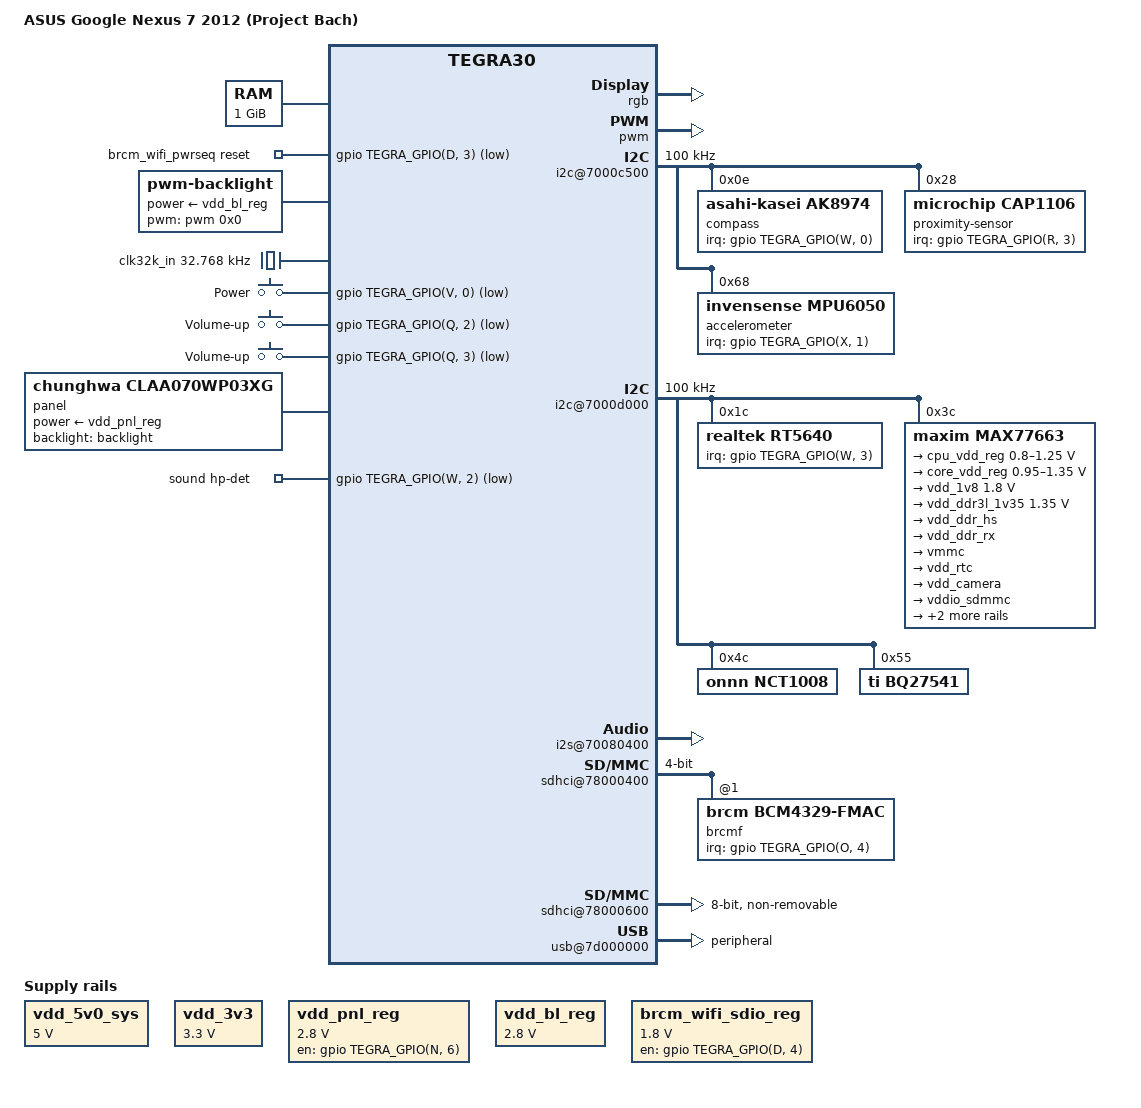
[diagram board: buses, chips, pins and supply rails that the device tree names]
/dts-v1/;

/memreserve/ 0xbeb00000 0x100000;

#include <dt-bindings/input/gpio-keys.h>
#include <dt-bindings/input/input.h>
#include <dt-bindings/mfd/max77620.h>
#include <dt-bindings/thermal/thermal.h>
#include "tegra30.dtsi"
#include "tegra30-cpu-opp.dtsi"
#include "tegra30-cpu-opp-microvolt.dtsi"

/ {
	compatible = "asus,tilapia", "nvidia,tegra30";
	model = "ASUS Google Nexus 7 2012 (Project Bach)";

	aliases {
		rtc0 = "/i2c@7000d000/max77663@3c";
		rtc1 = "/rtc@7000e000";
	};

	memory@80000000 {
		reg = <0x80000000 0x40000000>;
	};

	reserved-memory {
		#address-cells = <1>;
		#size-cells = <1>;
		ranges;

		linux,cma {
			compatible = "shared-dma-pool";
			alloc-ranges = <0x80000000 0x3fe00000>;
			size = <0x10000000>; /* 256MiB */
			linux,cma-default;
			reusable;
		};

		trust_zone@bfe00000 {
			reg = <0xbfe00000 0x200000>;
			no-map;
		};

		ramoops: ramoops@bfdf0000 {
			compatible = "ramoops";
			reg = <0xbfdf0000 0x10000>; /* 64kB */
			console-size = <0x4000>; /* 16kB */
			record-size = <0x4000>; /* 16kB */

			status = "disabled";
		};
	};

	host1x@50000000 {
		dc@54200000 {
			rgb {
				status = "okay";

				nvidia,panel = <&panel>;
			};
		};
	};

	pinmux@70000868 {
		pinctrl-names = "default";
		pinctrl-0 = <&state_default>;

		state_default: pinmux {
			clk_32k_out_pa0 {
				nvidia,pins = "clk_32k_out_pa0";
				nvidia,function = "blink";
				nvidia,pull = <TEGRA_PIN_PULL_NONE>;
				nvidia,tristate = <TEGRA_PIN_DISABLE>;
				nvidia,enable-input = <TEGRA_PIN_DISABLE>;
			};
			uart3_cts_n_pa1 {
				nvidia,pins = "uart3_cts_n_pa1";
				nvidia,function = "uartc";
				nvidia,pull = <TEGRA_PIN_PULL_NONE>;
				nvidia,tristate = <TEGRA_PIN_DISABLE>;
				nvidia,enable-input = <TEGRA_PIN_ENABLE>;
			};
			dap2_fs_pa2 {
				nvidia,pins = "dap2_fs_pa2";
				nvidia,function = "i2s1";
				nvidia,pull = <TEGRA_PIN_PULL_NONE>;
				nvidia,tristate = <TEGRA_PIN_DISABLE>;
				nvidia,enable-input = <TEGRA_PIN_ENABLE>;
			};
			dap2_sclk_pa3 {
				nvidia,pins = "dap2_sclk_pa3";
				nvidia,function = "i2s1";
				nvidia,pull = <TEGRA_PIN_PULL_NONE>;
				nvidia,tristate = <TEGRA_PIN_DISABLE>;
				nvidia,enable-input = <TEGRA_PIN_ENABLE>;
			};
			dap2_din_pa4 {
				nvidia,pins = "dap2_din_pa4";
				nvidia,function = "i2s1";
				nvidia,pull = <TEGRA_PIN_PULL_NONE>;
				nvidia,tristate = <TEGRA_PIN_DISABLE>;
				nvidia,enable-input = <TEGRA_PIN_ENABLE>;
			};
			dap2_dout_pa5 {
				nvidia,pins = "dap2_dout_pa5";
				nvidia,function = "i2s1";
				nvidia,pull = <TEGRA_PIN_PULL_NONE>;
				nvidia,tristate = <TEGRA_PIN_DISABLE>;
				nvidia,enable-input = <TEGRA_PIN_ENABLE>;
			};
			sdmmc3_clk_pa6 {
				nvidia,pins = "sdmmc3_clk_pa6";
				nvidia,function = "sdmmc3";
				nvidia,pull = <TEGRA_PIN_PULL_NONE>;
				nvidia,tristate = <TEGRA_PIN_DISABLE>;
				nvidia,enable-input = <TEGRA_PIN_ENABLE>;
			};
			sdmmc3_cmd_pa7 {
				nvidia,pins = "sdmmc3_cmd_pa7";
				nvidia,function = "sdmmc3";
				nvidia,pull = <TEGRA_PIN_PULL_UP>;
				nvidia,tristate = <TEGRA_PIN_DISABLE>;
				nvidia,enable-input = <TEGRA_PIN_ENABLE>;
			};
			gmi_a17_pb0 {
				nvidia,pins = "gmi_a17_pb0";
				nvidia,function = "uartd";
				nvidia,pull = <TEGRA_PIN_PULL_NONE>;
				nvidia,tristate = <TEGRA_PIN_DISABLE>;
				nvidia,enable-input = <TEGRA_PIN_ENABLE>;
			};
			gmi_a18_pb1 {
				nvidia,pins = "gmi_a18_pb1";
				nvidia,function = "uartd";
				nvidia,pull = <TEGRA_PIN_PULL_NONE>;
				nvidia,tristate = <TEGRA_PIN_DISABLE>;
				nvidia,enable-input = <TEGRA_PIN_ENABLE>;
			};
			lcd_pwr0_pb2 {
				nvidia,pins = "lcd_pwr0_pb2";
				nvidia,function = "displaya";
				nvidia,pull = <TEGRA_PIN_PULL_NONE>;
				nvidia,tristate = <TEGRA_PIN_DISABLE>;
				nvidia,enable-input = <TEGRA_PIN_DISABLE>;
			};
			lcd_pclk_pb3 {
				nvidia,pins = "lcd_pclk_pb3";
				nvidia,function = "displaya";
				nvidia,pull = <TEGRA_PIN_PULL_NONE>;
				nvidia,tristate = <TEGRA_PIN_DISABLE>;
				nvidia,enable-input = <TEGRA_PIN_ENABLE>;
			};
			sdmmc3_dat3_pb4 {
				nvidia,pins = "sdmmc3_dat3_pb4";
				nvidia,function = "sdmmc3";
				nvidia,pull = <TEGRA_PIN_PULL_UP>;
				nvidia,tristate = <TEGRA_PIN_DISABLE>;
				nvidia,enable-input = <TEGRA_PIN_ENABLE>;
			};
			sdmmc3_dat2_pb5 {
				nvidia,pins = "sdmmc3_dat2_pb5";
				nvidia,function = "sdmmc3";
				nvidia,pull = <TEGRA_PIN_PULL_UP>;
				nvidia,tristate = <TEGRA_PIN_DISABLE>;
				nvidia,enable-input = <TEGRA_PIN_ENABLE>;
			};
			sdmmc3_dat1_pb6 {
				nvidia,pins = "sdmmc3_dat1_pb6";
				nvidia,function = "sdmmc3";
				nvidia,pull = <TEGRA_PIN_PULL_UP>;
				nvidia,tristate = <TEGRA_PIN_DISABLE>;
				nvidia,enable-input = <TEGRA_PIN_ENABLE>;
			};
			sdmmc3_dat0_pb7 {
				nvidia,pins = "sdmmc3_dat0_pb7";
				nvidia,function = "sdmmc3";
				nvidia,pull = <TEGRA_PIN_PULL_UP>;
				nvidia,tristate = <TEGRA_PIN_DISABLE>;
				nvidia,enable-input = <TEGRA_PIN_ENABLE>;
			};
			uart3_rts_n_pc0 {
				nvidia,pins = "uart3_rts_n_pc0";
				nvidia,function = "uartc";
				nvidia,pull = <TEGRA_PIN_PULL_NONE>;
				nvidia,tristate = <TEGRA_PIN_DISABLE>;
				nvidia,enable-input = <TEGRA_PIN_DISABLE>;
			};
			lcd_pwr1_pc1 {
				nvidia,pins = "lcd_pwr1_pc1";
				nvidia,function = "displaya";
				nvidia,pull = <TEGRA_PIN_PULL_NONE>;
				nvidia,tristate = <TEGRA_PIN_DISABLE>;
				nvidia,enable-input = <TEGRA_PIN_DISABLE>;
			};
			uart2_txd_pc2 {
				nvidia,pins = "uart2_txd_pc2";
				nvidia,function = "uartb";
				nvidia,pull = <TEGRA_PIN_PULL_NONE>;
				nvidia,tristate = <TEGRA_PIN_DISABLE>;
				nvidia,enable-input = <TEGRA_PIN_DISABLE>;
			};
			uart2_rxd_pc3 {
				nvidia,pins = "uart2_rxd_pc3";
				nvidia,function = "uartb";
				nvidia,pull = <TEGRA_PIN_PULL_NONE>;
				nvidia,tristate = <TEGRA_PIN_DISABLE>;
				nvidia,enable-input = <TEGRA_PIN_ENABLE>;
			};
			gen1_i2c_scl_pc4 {
				nvidia,pins = "gen1_i2c_scl_pc4";
				nvidia,function = "i2c1";
				nvidia,pull = <TEGRA_PIN_PULL_NONE>;
				nvidia,tristate = <TEGRA_PIN_DISABLE>;
				nvidia,enable-input = <TEGRA_PIN_ENABLE>;
				nvidia,open-drain = <TEGRA_PIN_DISABLE>;
			};
			gen1_i2c_sda_pc5 {
				nvidia,pins = "gen1_i2c_sda_pc5";
				nvidia,function = "i2c1";
				nvidia,pull = <TEGRA_PIN_PULL_NONE>;
				nvidia,tristate = <TEGRA_PIN_DISABLE>;
				nvidia,enable-input = <TEGRA_PIN_ENABLE>;
				nvidia,open-drain = <TEGRA_PIN_DISABLE>;
			};
			lcd_pwr2_pc6 {
				nvidia,pins = "lcd_pwr2_pc6";
				nvidia,function = "displaya";
				nvidia,pull = <TEGRA_PIN_PULL_DOWN>;
				nvidia,tristate = <TEGRA_PIN_DISABLE>;
				nvidia,enable-input = <TEGRA_PIN_DISABLE>;
			};
			gmi_wp_n_pc7 {
				nvidia,pins = "gmi_wp_n_pc7";
				nvidia,function = "rsvd1";
				nvidia,pull = <TEGRA_PIN_PULL_NONE>;
				nvidia,tristate = <TEGRA_PIN_ENABLE>;
				nvidia,enable-input = <TEGRA_PIN_ENABLE>;
			};
			sdmmc3_dat5_pd0 {
				nvidia,pins = "sdmmc3_dat5_pd0";
				nvidia,function = "sdmmc3";
				nvidia,pull = <TEGRA_PIN_PULL_NONE>;
				nvidia,tristate = <TEGRA_PIN_DISABLE>;
				nvidia,enable-input = <TEGRA_PIN_DISABLE>;
			};
			sdmmc3_dat4_pd1 {
				nvidia,pins = "sdmmc3_dat4_pd1";
				nvidia,function = "sdmmc3";
				nvidia,pull = <TEGRA_PIN_PULL_UP>;
				nvidia,tristate = <TEGRA_PIN_DISABLE>;
				nvidia,enable-input = <TEGRA_PIN_ENABLE>;
			};
			lcd_dc1_pd2 {
				nvidia,pins = "lcd_dc1_pd2";
				nvidia,function = "displaya";
				nvidia,pull = <TEGRA_PIN_PULL_DOWN>;
				nvidia,tristate = <TEGRA_PIN_DISABLE>;
				nvidia,enable-input = <TEGRA_PIN_DISABLE>;
			};
			sdmmc3_dat6_pd3 {
				nvidia,pins = "sdmmc3_dat6_pd3";
				nvidia,function = "sdmmc3";
				nvidia,pull = <TEGRA_PIN_PULL_UP>;
				nvidia,tristate = <TEGRA_PIN_DISABLE>;
				nvidia,enable-input = <TEGRA_PIN_ENABLE>;
			};
			sdmmc3_dat7_pd4 {
				nvidia,pins = "sdmmc3_dat7_pd4";
				nvidia,function = "sdmmc3";
				nvidia,pull = <TEGRA_PIN_PULL_UP>;
				nvidia,tristate = <TEGRA_PIN_DISABLE>;
				nvidia,enable-input = <TEGRA_PIN_ENABLE>;
			};
			vi_d1_pd5 {
				nvidia,pins = "vi_d1_pd5";
				nvidia,function = "sdmmc2";
				nvidia,pull = <TEGRA_PIN_PULL_DOWN>;
				nvidia,tristate = <TEGRA_PIN_ENABLE>;
				nvidia,enable-input = <TEGRA_PIN_ENABLE>;
			};
			vi_vsync_pd6 {
				nvidia,pins = "vi_vsync_pd6";
				nvidia,function = "ddr";
				nvidia,pull = <TEGRA_PIN_PULL_DOWN>;
				nvidia,tristate = <TEGRA_PIN_ENABLE>;
				nvidia,enable-input = <TEGRA_PIN_ENABLE>;
			};
			vi_hsync_pd7 {
				nvidia,pins = "vi_hsync_pd7";
				nvidia,function = "ddr";
				nvidia,pull = <TEGRA_PIN_PULL_DOWN>;
				nvidia,tristate = <TEGRA_PIN_ENABLE>;
				nvidia,enable-input = <TEGRA_PIN_ENABLE>;
			};
			lcd_d0_pe0 {
				nvidia,pins = "lcd_d0_pe0";
				nvidia,function = "displaya";
				nvidia,pull = <TEGRA_PIN_PULL_NONE>;
				nvidia,tristate = <TEGRA_PIN_DISABLE>;
				nvidia,enable-input = <TEGRA_PIN_ENABLE>;
			};
			lcd_d1_pe1 {
				nvidia,pins = "lcd_d1_pe1";
				nvidia,function = "displaya";
				nvidia,pull = <TEGRA_PIN_PULL_NONE>;
				nvidia,tristate = <TEGRA_PIN_DISABLE>;
				nvidia,enable-input = <TEGRA_PIN_ENABLE>;
			};
			lcd_d2_pe2 {
				nvidia,pins = "lcd_d2_pe2";
				nvidia,function = "displaya";
				nvidia,pull = <TEGRA_PIN_PULL_NONE>;
				nvidia,tristate = <TEGRA_PIN_DISABLE>;
				nvidia,enable-input = <TEGRA_PIN_ENABLE>;
			};
			lcd_d3_pe3 {
				nvidia,pins = "lcd_d3_pe3";
				nvidia,function = "displaya";
				nvidia,pull = <TEGRA_PIN_PULL_NONE>;
				nvidia,tristate = <TEGRA_PIN_DISABLE>;
				nvidia,enable-input = <TEGRA_PIN_ENABLE>;
			};
			lcd_d4_pe4 {
				nvidia,pins = "lcd_d4_pe4";
				nvidia,function = "displaya";
				nvidia,pull = <TEGRA_PIN_PULL_NONE>;
				nvidia,tristate = <TEGRA_PIN_DISABLE>;
				nvidia,enable-input = <TEGRA_PIN_ENABLE>;
			};
			lcd_d5_pe5 {
				nvidia,pins = "lcd_d5_pe5";
				nvidia,function = "displaya";
				nvidia,pull = <TEGRA_PIN_PULL_NONE>;
				nvidia,tristate = <TEGRA_PIN_DISABLE>;
				nvidia,enable-input = <TEGRA_PIN_ENABLE>;
			};
			lcd_d6_pe6 {
				nvidia,pins = "lcd_d6_pe6";
				nvidia,function = "displaya";
				nvidia,pull = <TEGRA_PIN_PULL_NONE>;
				nvidia,tristate = <TEGRA_PIN_DISABLE>;
				nvidia,enable-input = <TEGRA_PIN_ENABLE>;
			};
			lcd_d7_pe7 {
				nvidia,pins = "lcd_d7_pe7";
				nvidia,function = "displaya";
				nvidia,pull = <TEGRA_PIN_PULL_NONE>;
				nvidia,tristate = <TEGRA_PIN_DISABLE>;
				nvidia,enable-input = <TEGRA_PIN_ENABLE>;
			};
			lcd_d8_pf0 {
				nvidia,pins = "lcd_d8_pf0";
				nvidia,function = "displaya";
				nvidia,pull = <TEGRA_PIN_PULL_NONE>;
				nvidia,tristate = <TEGRA_PIN_DISABLE>;
				nvidia,enable-input = <TEGRA_PIN_ENABLE>;
			};
			lcd_d9_pf1 {
				nvidia,pins = "lcd_d9_pf1";
				nvidia,function = "displaya";
				nvidia,pull = <TEGRA_PIN_PULL_NONE>;
				nvidia,tristate = <TEGRA_PIN_DISABLE>;
				nvidia,enable-input = <TEGRA_PIN_ENABLE>;
			};
			lcd_d10_pf2 {
				nvidia,pins = "lcd_d10_pf2";
				nvidia,function = "displaya";
				nvidia,pull = <TEGRA_PIN_PULL_NONE>;
				nvidia,tristate = <TEGRA_PIN_DISABLE>;
				nvidia,enable-input = <TEGRA_PIN_ENABLE>;
			};
			lcd_d11_pf3 {
				nvidia,pins = "lcd_d11_pf3";
				nvidia,function = "displaya";
				nvidia,pull = <TEGRA_PIN_PULL_NONE>;
				nvidia,tristate = <TEGRA_PIN_DISABLE>;
				nvidia,enable-input = <TEGRA_PIN_ENABLE>;
			};
			lcd_d12_pf4 {
				nvidia,pins = "lcd_d12_pf4";
				nvidia,function = "displaya";
				nvidia,pull = <TEGRA_PIN_PULL_NONE>;
				nvidia,tristate = <TEGRA_PIN_DISABLE>;
				nvidia,enable-input = <TEGRA_PIN_ENABLE>;
			};
			lcd_d13_pf5 {
				nvidia,pins = "lcd_d13_pf5";
				nvidia,function = "displaya";
				nvidia,pull = <TEGRA_PIN_PULL_NONE>;
				nvidia,tristate = <TEGRA_PIN_DISABLE>;
				nvidia,enable-input = <TEGRA_PIN_ENABLE>;
			};
			lcd_d14_pf6 {
				nvidia,pins = "lcd_d14_pf6";
				nvidia,function = "displaya";
				nvidia,pull = <TEGRA_PIN_PULL_NONE>;
				nvidia,tristate = <TEGRA_PIN_DISABLE>;
				nvidia,enable-input = <TEGRA_PIN_ENABLE>;
			};
			lcd_d15_pf7 {
				nvidia,pins = "lcd_d15_pf7";
				nvidia,function = "displaya";
				nvidia,pull = <TEGRA_PIN_PULL_NONE>;
				nvidia,tristate = <TEGRA_PIN_DISABLE>;
				nvidia,enable-input = <TEGRA_PIN_ENABLE>;
			};
			gmi_ad0_pg0 {
				nvidia,pins = "gmi_ad0_pg0";
				nvidia,function = "rsvd1";
				nvidia,pull = <TEGRA_PIN_PULL_NONE>;
				nvidia,tristate = <TEGRA_PIN_DISABLE>;
				nvidia,enable-input = <TEGRA_PIN_DISABLE>;
			};
			gmi_ad1_pg1 {
				nvidia,pins = "gmi_ad1_pg1";
				nvidia,function = "rsvd1";
				nvidia,pull = <TEGRA_PIN_PULL_NONE>;
				nvidia,tristate = <TEGRA_PIN_DISABLE>;
				nvidia,enable-input = <TEGRA_PIN_DISABLE>;
			};
			gmi_ad2_pg2 {
				nvidia,pins = "gmi_ad2_pg2";
				nvidia,function = "rsvd1";
				nvidia,pull = <TEGRA_PIN_PULL_DOWN>;
				nvidia,tristate = <TEGRA_PIN_DISABLE>;
				nvidia,enable-input = <TEGRA_PIN_DISABLE>;
			};
			gmi_ad3_pg3 {
				nvidia,pins = "gmi_ad3_pg3";
				nvidia,function = "rsvd1";
				nvidia,pull = <TEGRA_PIN_PULL_DOWN>;
				nvidia,tristate = <TEGRA_PIN_DISABLE>;
				nvidia,enable-input = <TEGRA_PIN_DISABLE>;
			};
			gmi_ad4_pg4 {
				nvidia,pins = "gmi_ad4_pg4";
				nvidia,function = "nand";
				nvidia,pull = <TEGRA_PIN_PULL_NONE>;
				nvidia,tristate = <TEGRA_PIN_DISABLE>;
				nvidia,enable-input = <TEGRA_PIN_ENABLE>;
			};
			gmi_ad5_pg5 {
				nvidia,pins = "gmi_ad5_pg5";
				nvidia,function = "nand";
				nvidia,pull = <TEGRA_PIN_PULL_NONE>;
				nvidia,tristate = <TEGRA_PIN_DISABLE>;
				nvidia,enable-input = <TEGRA_PIN_ENABLE>;
			};
			gmi_ad6_pg6 {
				nvidia,pins = "gmi_ad6_pg6";
				nvidia,function = "rsvd1";
				nvidia,pull = <TEGRA_PIN_PULL_DOWN>;
				nvidia,tristate = <TEGRA_PIN_DISABLE>;
				nvidia,enable-input = <TEGRA_PIN_DISABLE>;
			};
			gmi_ad7_pg7 {
				nvidia,pins = "gmi_ad7_pg7";
				nvidia,function = "rsvd1";
				nvidia,pull = <TEGRA_PIN_PULL_DOWN>;
				nvidia,tristate = <TEGRA_PIN_DISABLE>;
				nvidia,enable-input = <TEGRA_PIN_DISABLE>;
			};
			gmi_ad8_ph0 {
				nvidia,pins = "gmi_ad8_ph0";
				nvidia,function = "pwm0";
				nvidia,pull = <TEGRA_PIN_PULL_NONE>;
				nvidia,tristate = <TEGRA_PIN_DISABLE>;
				nvidia,enable-input = <TEGRA_PIN_DISABLE>;
			};
			gmi_ad9_ph1 {
				nvidia,pins = "gmi_ad9_ph1";
				nvidia,function = "rsvd4";
				nvidia,pull = <TEGRA_PIN_PULL_DOWN>;
				nvidia,tristate = <TEGRA_PIN_DISABLE>;
				nvidia,enable-input = <TEGRA_PIN_DISABLE>;
			};
			gmi_ad10_ph2 {
				nvidia,pins = "gmi_ad10_ph2";
				nvidia,function = "pwm2";
				nvidia,pull = <TEGRA_PIN_PULL_NONE>;
				nvidia,tristate = <TEGRA_PIN_ENABLE>;
				nvidia,enable-input = <TEGRA_PIN_DISABLE>;
			};
			gmi_ad11_ph3 {
				nvidia,pins = "gmi_ad11_ph3";
				nvidia,function = "pwm3";
				nvidia,pull = <TEGRA_PIN_PULL_NONE>;
				nvidia,tristate = <TEGRA_PIN_DISABLE>;
				nvidia,enable-input = <TEGRA_PIN_DISABLE>;
			};
			gmi_ad12_ph4 {
				nvidia,pins = "gmi_ad12_ph4";
				nvidia,function = "rsvd1";
				nvidia,pull = <TEGRA_PIN_PULL_NONE>;
				nvidia,tristate = <TEGRA_PIN_ENABLE>;
				nvidia,enable-input = <TEGRA_PIN_ENABLE>;
			};
			gmi_ad13_ph5 {
				nvidia,pins = "gmi_ad13_ph5";
				nvidia,function = "rsvd1";
				nvidia,pull = <TEGRA_PIN_PULL_NONE>;
				nvidia,tristate = <TEGRA_PIN_ENABLE>;
				nvidia,enable-input = <TEGRA_PIN_DISABLE>;
			};
			gmi_ad14_ph6 {
				nvidia,pins = "gmi_ad14_ph6";
				nvidia,function = "rsvd1";
				nvidia,pull = <TEGRA_PIN_PULL_NONE>;
				nvidia,tristate = <TEGRA_PIN_DISABLE>;
				nvidia,enable-input = <TEGRA_PIN_DISABLE>;
			};
			gmi_ad15_ph7 {
				nvidia,pins = "gmi_ad15_ph7";
				nvidia,function = "rsvd1";
				nvidia,pull = <TEGRA_PIN_PULL_UP>;
				nvidia,tristate = <TEGRA_PIN_DISABLE>;
				nvidia,enable-input = <TEGRA_PIN_DISABLE>;
			};
			gmi_wr_n_pi0 {
				nvidia,pins = "gmi_wr_n_pi0";
				nvidia,function = "rsvd1";
				nvidia,pull = <TEGRA_PIN_PULL_NONE>;
				nvidia,tristate = <TEGRA_PIN_ENABLE>;
				nvidia,enable-input = <TEGRA_PIN_DISABLE>;
			};
			gmi_oe_n_pi1 {
				nvidia,pins = "gmi_oe_n_pi1";
				nvidia,function = "rsvd1";
				nvidia,pull = <TEGRA_PIN_PULL_NONE>;
				nvidia,tristate = <TEGRA_PIN_ENABLE>;
				nvidia,enable-input = <TEGRA_PIN_DISABLE>;
			};
			gmi_dqs_pi2 {
				nvidia,pins = "gmi_dqs_pi2";
				nvidia,function = "rsvd1";
				nvidia,pull = <TEGRA_PIN_PULL_NONE>;
				nvidia,tristate = <TEGRA_PIN_DISABLE>;
				nvidia,enable-input = <TEGRA_PIN_ENABLE>;
			};
			gmi_cs6_n_pi3 {
				nvidia,pins = "gmi_cs6_n_pi3";
				nvidia,function = "gmi";
				nvidia,pull = <TEGRA_PIN_PULL_NONE>;
				nvidia,tristate = <TEGRA_PIN_ENABLE>;
				nvidia,enable-input = <TEGRA_PIN_ENABLE>;
			};
			gmi_rst_n_pi4 {
				nvidia,pins = "gmi_rst_n_pi4";
				nvidia,function = "nand";
				nvidia,pull = <TEGRA_PIN_PULL_UP>;
				nvidia,tristate = <TEGRA_PIN_DISABLE>;
				nvidia,enable-input = <TEGRA_PIN_DISABLE>;
			};
			gmi_iordy_pi5 {
				nvidia,pins = "gmi_iordy_pi5";
				nvidia,function = "rsvd1";
				nvidia,pull = <TEGRA_PIN_PULL_UP>;
				nvidia,tristate = <TEGRA_PIN_DISABLE>;
				nvidia,enable-input = <TEGRA_PIN_ENABLE>;
			};
			gmi_cs7_n_pi6 {
				nvidia,pins = "gmi_cs7_n_pi6";
				nvidia,function = "nand";
				nvidia,pull = <TEGRA_PIN_PULL_NONE>;
				nvidia,tristate = <TEGRA_PIN_ENABLE>;
				nvidia,enable-input = <TEGRA_PIN_DISABLE>;
			};
			gmi_wait_pi7 {
				nvidia,pins = "gmi_wait_pi7";
				nvidia,function = "rsvd1";
				nvidia,pull = <TEGRA_PIN_PULL_NONE>;
				nvidia,tristate = <TEGRA_PIN_ENABLE>;
				nvidia,enable-input = <TEGRA_PIN_ENABLE>;
			};
			gmi_cs0_n_pj0 {
				nvidia,pins = "gmi_cs0_n_pj0";
				nvidia,function = "rsvd1";
				nvidia,pull = <TEGRA_PIN_PULL_NONE>;
				nvidia,tristate = <TEGRA_PIN_ENABLE>;
				nvidia,enable-input = <TEGRA_PIN_ENABLE>;
			};
			lcd_de_pj1 {
				nvidia,pins = "lcd_de_pj1";
				nvidia,function = "displaya";
				nvidia,pull = <TEGRA_PIN_PULL_NONE>;
				nvidia,tristate = <TEGRA_PIN_DISABLE>;
				nvidia,enable-input = <TEGRA_PIN_ENABLE>;
			};
			gmi_cs1_n_pj2 {
				nvidia,pins = "gmi_cs1_n_pj2";
				nvidia,function = "rsvd1";
				nvidia,pull = <TEGRA_PIN_PULL_NONE>;
				nvidia,tristate = <TEGRA_PIN_ENABLE>;
				nvidia,enable-input = <TEGRA_PIN_ENABLE>;
			};
			lcd_hsync_pj3 {
				nvidia,pins = "lcd_hsync_pj3";
				nvidia,function = "displaya";
				nvidia,pull = <TEGRA_PIN_PULL_NONE>;
				nvidia,tristate = <TEGRA_PIN_DISABLE>;
				nvidia,enable-input = <TEGRA_PIN_ENABLE>;
			};
			lcd_vsync_pj4 {
				nvidia,pins = "lcd_vsync_pj4";
				nvidia,function = "displaya";
				nvidia,pull = <TEGRA_PIN_PULL_NONE>;
				nvidia,tristate = <TEGRA_PIN_DISABLE>;
				nvidia,enable-input = <TEGRA_PIN_ENABLE>;
			};
			uart2_cts_n_pj5 {
				nvidia,pins = "uart2_cts_n_pj5";
				nvidia,function = "uartb";
				nvidia,pull = <TEGRA_PIN_PULL_NONE>;
				nvidia,tristate = <TEGRA_PIN_DISABLE>;
				nvidia,enable-input = <TEGRA_PIN_ENABLE>;
			};
			uart2_rts_n_pj6 {
				nvidia,pins = "uart2_rts_n_pj6";
				nvidia,function = "uartb";
				nvidia,pull = <TEGRA_PIN_PULL_NONE>;
				nvidia,tristate = <TEGRA_PIN_DISABLE>;
				nvidia,enable-input = <TEGRA_PIN_DISABLE>;
			};
			gmi_a16_pj7 {
				nvidia,pins = "gmi_a16_pj7";
				nvidia,function = "uartd";
				nvidia,pull = <TEGRA_PIN_PULL_NONE>;
				nvidia,tristate = <TEGRA_PIN_DISABLE>;
				nvidia,enable-input = <TEGRA_PIN_DISABLE>;
			};
			gmi_adv_n_pk0 {
				nvidia,pins = "gmi_adv_n_pk0";
				nvidia,function = "rsvd1";
				nvidia,pull = <TEGRA_PIN_PULL_NONE>;
				nvidia,tristate = <TEGRA_PIN_ENABLE>;
				nvidia,enable-input = <TEGRA_PIN_DISABLE>;
			};
			gmi_clk_pk1 {
				nvidia,pins = "gmi_clk_pk1";
				nvidia,function = "nand";
				nvidia,pull = <TEGRA_PIN_PULL_NONE>;
				nvidia,tristate = <TEGRA_PIN_ENABLE>;
				nvidia,enable-input = <TEGRA_PIN_DISABLE>;
			};
			gmi_cs4_n_pk2 {
				nvidia,pins = "gmi_cs4_n_pk2";
				nvidia,function = "rsvd1";
				nvidia,pull = <TEGRA_PIN_PULL_NONE>;
				nvidia,tristate = <TEGRA_PIN_ENABLE>;
				nvidia,enable-input = <TEGRA_PIN_ENABLE>;
			};
			gmi_cs2_n_pk3 {
				nvidia,pins = "gmi_cs2_n_pk3";
				nvidia,function = "rsvd1";
				nvidia,pull = <TEGRA_PIN_PULL_NONE>;
				nvidia,tristate = <TEGRA_PIN_ENABLE>;
				nvidia,enable-input = <TEGRA_PIN_ENABLE>;
			};
			gmi_cs3_n_pk4 {
				nvidia,pins = "gmi_cs3_n_pk4";
				nvidia,function = "rsvd1";
				nvidia,pull = <TEGRA_PIN_PULL_NONE>;
				nvidia,tristate = <TEGRA_PIN_ENABLE>;
				nvidia,enable-input = <TEGRA_PIN_ENABLE>;
			};
			spdif_out_pk5 {
				nvidia,pins = "spdif_out_pk5";
				nvidia,function = "spdif";
				nvidia,pull = <TEGRA_PIN_PULL_NONE>;
				nvidia,tristate = <TEGRA_PIN_DISABLE>;
				nvidia,enable-input = <TEGRA_PIN_DISABLE>;
			};
			spdif_in_pk6 {
				nvidia,pins = "spdif_in_pk6";
				nvidia,function = "spdif";
				nvidia,pull = <TEGRA_PIN_PULL_NONE>;
				nvidia,tristate = <TEGRA_PIN_DISABLE>;
				nvidia,enable-input = <TEGRA_PIN_ENABLE>;
			};
			gmi_a19_pk7 {
				nvidia,pins = "gmi_a19_pk7";
				nvidia,function = "uartd";
				nvidia,pull = <TEGRA_PIN_PULL_NONE>;
				nvidia,tristate = <TEGRA_PIN_DISABLE>;
				nvidia,enable-input = <TEGRA_PIN_DISABLE>;
			};
			vi_d2_pl0 {
				nvidia,pins = "vi_d2_pl0";
				nvidia,function = "sdmmc2";
				nvidia,pull = <TEGRA_PIN_PULL_DOWN>;
				nvidia,tristate = <TEGRA_PIN_ENABLE>;
				nvidia,enable-input = <TEGRA_PIN_ENABLE>;
			};
			vi_d3_pl1 {
				nvidia,pins = "vi_d3_pl1";
				nvidia,function = "sdmmc2";
				nvidia,pull = <TEGRA_PIN_PULL_DOWN>;
				nvidia,tristate = <TEGRA_PIN_ENABLE>;
				nvidia,enable-input = <TEGRA_PIN_ENABLE>;
			};
			vi_d4_pl2 {
				nvidia,pins = "vi_d4_pl2";
				nvidia,function = "vi";
				nvidia,pull = <TEGRA_PIN_PULL_UP>;
				nvidia,tristate = <TEGRA_PIN_DISABLE>;
				nvidia,enable-input = <TEGRA_PIN_ENABLE>;
			};
			vi_d5_pl3 {
				nvidia,pins = "vi_d5_pl3";
				nvidia,function = "sdmmc2";
				nvidia,pull = <TEGRA_PIN_PULL_DOWN>;
				nvidia,tristate = <TEGRA_PIN_ENABLE>;
				nvidia,enable-input = <TEGRA_PIN_ENABLE>;
			};
			vi_d6_pl4 {
				nvidia,pins = "vi_d6_pl4";
				nvidia,function = "vi";
				nvidia,pull = <TEGRA_PIN_PULL_UP>;
				nvidia,tristate = <TEGRA_PIN_DISABLE>;
				nvidia,enable-input = <TEGRA_PIN_ENABLE>;
			};
			vi_d7_pl5 {
				nvidia,pins = "vi_d7_pl5";
				nvidia,function = "sdmmc2";
				nvidia,pull = <TEGRA_PIN_PULL_DOWN>;
				nvidia,tristate = <TEGRA_PIN_ENABLE>;
				nvidia,enable-input = <TEGRA_PIN_ENABLE>;
			};
			vi_d8_pl6 {
				nvidia,pins = "vi_d8_pl6";
				nvidia,function = "sdmmc2";
				nvidia,pull = <TEGRA_PIN_PULL_DOWN>;
				nvidia,tristate = <TEGRA_PIN_ENABLE>;
				nvidia,enable-input = <TEGRA_PIN_ENABLE>;
			};
			vi_d9_pl7 {
				nvidia,pins = "vi_d9_pl7";
				nvidia,function = "sdmmc2";
				nvidia,pull = <TEGRA_PIN_PULL_DOWN>;
				nvidia,tristate = <TEGRA_PIN_ENABLE>;
				nvidia,enable-input = <TEGRA_PIN_ENABLE>;
			};
			lcd_d16_pm0 {
				nvidia,pins = "lcd_d16_pm0";
				nvidia,function = "displaya";
				nvidia,pull = <TEGRA_PIN_PULL_NONE>;
				nvidia,tristate = <TEGRA_PIN_DISABLE>;
				nvidia,enable-input = <TEGRA_PIN_ENABLE>;
			};
			lcd_d17_pm1 {
				nvidia,pins = "lcd_d17_pm1";
				nvidia,function = "displaya";
				nvidia,pull = <TEGRA_PIN_PULL_NONE>;
				nvidia,tristate = <TEGRA_PIN_DISABLE>;
				nvidia,enable-input = <TEGRA_PIN_ENABLE>;
			};
			lcd_d18_pm2 {
				nvidia,pins = "lcd_d18_pm2";
				nvidia,function = "displaya";
				nvidia,pull = <TEGRA_PIN_PULL_NONE>;
				nvidia,tristate = <TEGRA_PIN_DISABLE>;
				nvidia,enable-input = <TEGRA_PIN_ENABLE>;
			};
			lcd_d19_pm3 {
				nvidia,pins = "lcd_d19_pm3";
				nvidia,function = "displaya";
				nvidia,pull = <TEGRA_PIN_PULL_NONE>;
				nvidia,tristate = <TEGRA_PIN_DISABLE>;
				nvidia,enable-input = <TEGRA_PIN_ENABLE>;
			};
			lcd_d20_pm4 {
				nvidia,pins = "lcd_d20_pm4";
				nvidia,function = "displaya";
				nvidia,pull = <TEGRA_PIN_PULL_NONE>;
				nvidia,tristate = <TEGRA_PIN_DISABLE>;
				nvidia,enable-input = <TEGRA_PIN_ENABLE>;
			};
			lcd_d21_pm5 {
				nvidia,pins = "lcd_d21_pm5";
				nvidia,function = "displaya";
				nvidia,pull = <TEGRA_PIN_PULL_NONE>;
				nvidia,tristate = <TEGRA_PIN_DISABLE>;
				nvidia,enable-input = <TEGRA_PIN_ENABLE>;
			};
			lcd_d22_pm6 {
				nvidia,pins = "lcd_d22_pm6";
				nvidia,function = "displaya";
				nvidia,pull = <TEGRA_PIN_PULL_NONE>;
				nvidia,tristate = <TEGRA_PIN_DISABLE>;
				nvidia,enable-input = <TEGRA_PIN_ENABLE>;
			};
			lcd_d23_pm7 {
				nvidia,pins = "lcd_d23_pm7";
				nvidia,function = "displaya";
				nvidia,pull = <TEGRA_PIN_PULL_NONE>;
				nvidia,tristate = <TEGRA_PIN_DISABLE>;
				nvidia,enable-input = <TEGRA_PIN_ENABLE>;
			};
			dap1_fs_pn0 {
				nvidia,pins = "dap1_fs_pn0";
				nvidia,function = "i2s0";
				nvidia,pull = <TEGRA_PIN_PULL_NONE>;
				nvidia,tristate = <TEGRA_PIN_DISABLE>;
				nvidia,enable-input = <TEGRA_PIN_ENABLE>;
			};
			dap1_din_pn1 {
				nvidia,pins = "dap1_din_pn1";
				nvidia,function = "i2s0";
				nvidia,pull = <TEGRA_PIN_PULL_NONE>;
				nvidia,tristate = <TEGRA_PIN_DISABLE>;
				nvidia,enable-input = <TEGRA_PIN_ENABLE>;
			};
			dap1_dout_pn2 {
				nvidia,pins = "dap1_dout_pn2";
				nvidia,function = "i2s0";
				nvidia,pull = <TEGRA_PIN_PULL_NONE>;
				nvidia,tristate = <TEGRA_PIN_DISABLE>;
				nvidia,enable-input = <TEGRA_PIN_ENABLE>;
			};
			dap1_sclk_pn3 {
				nvidia,pins = "dap1_sclk_pn3";
				nvidia,function = "i2s0";
				nvidia,pull = <TEGRA_PIN_PULL_NONE>;
				nvidia,tristate = <TEGRA_PIN_DISABLE>;
				nvidia,enable-input = <TEGRA_PIN_ENABLE>;
			};
			lcd_cs0_n_pn4 {
				nvidia,pins = "lcd_cs0_n_pn4";
				nvidia,function = "displaya";
				nvidia,pull = <TEGRA_PIN_PULL_NONE>;
				nvidia,tristate = <TEGRA_PIN_DISABLE>;
				nvidia,enable-input = <TEGRA_PIN_ENABLE>;
			};
			lcd_sdout_pn5 {
				nvidia,pins = "lcd_sdout_pn5";
				nvidia,function = "displaya";
				nvidia,pull = <TEGRA_PIN_PULL_NONE>;
				nvidia,tristate = <TEGRA_PIN_DISABLE>;
				nvidia,enable-input = <TEGRA_PIN_ENABLE>;
			};
			lcd_dc0_pn6 {
				nvidia,pins = "lcd_dc0_pn6";
				nvidia,function = "displaya";
				nvidia,pull = <TEGRA_PIN_PULL_NONE>;
				nvidia,tristate = <TEGRA_PIN_DISABLE>;
				nvidia,enable-input = <TEGRA_PIN_ENABLE>;
			};
			hdmi_int_pn7 {
				nvidia,pins = "hdmi_int_pn7";
				nvidia,function = "hdmi";
				nvidia,pull = <TEGRA_PIN_PULL_NONE>;
				nvidia,tristate = <TEGRA_PIN_ENABLE>;
				nvidia,enable-input = <TEGRA_PIN_ENABLE>;
			};
			ulpi_data7_po0 {
				nvidia,pins = "ulpi_data7_po0";
				nvidia,function = "uarta";
				nvidia,pull = <TEGRA_PIN_PULL_UP>;
				nvidia,tristate = <TEGRA_PIN_ENABLE>;
				nvidia,enable-input = <TEGRA_PIN_DISABLE>;
			};
			ulpi_data0_po1 {
				nvidia,pins = "ulpi_data0_po1";
				nvidia,function = "uarta";
				nvidia,pull = <TEGRA_PIN_PULL_DOWN>;
				nvidia,tristate = <TEGRA_PIN_ENABLE>;
				nvidia,enable-input = <TEGRA_PIN_DISABLE>;
			};
			ulpi_data1_po2 {
				nvidia,pins = "ulpi_data1_po2";
				nvidia,function = "uarta";
				nvidia,pull = <TEGRA_PIN_PULL_UP>;
				nvidia,tristate = <TEGRA_PIN_ENABLE>;
				nvidia,enable-input = <TEGRA_PIN_ENABLE>;
			};
			ulpi_data2_po3 {
				nvidia,pins = "ulpi_data2_po3";
				nvidia,function = "uarta";
				nvidia,pull = <TEGRA_PIN_PULL_UP>;
				nvidia,tristate = <TEGRA_PIN_ENABLE>;
				nvidia,enable-input = <TEGRA_PIN_ENABLE>;
			};
			ulpi_data3_po4 {
				nvidia,pins = "ulpi_data3_po4";
				nvidia,function = "ulpi";
				nvidia,pull = <TEGRA_PIN_PULL_NONE>;
				nvidia,tristate = <TEGRA_PIN_DISABLE>;
				nvidia,enable-input = <TEGRA_PIN_ENABLE>;
			};
			ulpi_data4_po5 {
				nvidia,pins = "ulpi_data4_po5";
				nvidia,function = "uarta";
				nvidia,pull = <TEGRA_PIN_PULL_UP>;
				nvidia,tristate = <TEGRA_PIN_ENABLE>;
				nvidia,enable-input = <TEGRA_PIN_ENABLE>;
			};
			ulpi_data5_po6 {
				nvidia,pins = "ulpi_data5_po6";
				nvidia,function = "uarta";
				nvidia,pull = <TEGRA_PIN_PULL_UP>;
				nvidia,tristate = <TEGRA_PIN_ENABLE>;
				nvidia,enable-input = <TEGRA_PIN_ENABLE>;
			};
			ulpi_data6_po7 {
				nvidia,pins = "ulpi_data6_po7";
				nvidia,function = "uarta";
				nvidia,pull = <TEGRA_PIN_PULL_UP>;
				nvidia,tristate = <TEGRA_PIN_ENABLE>;
				nvidia,enable-input = <TEGRA_PIN_ENABLE>;
			};
			dap3_fs_pp0 {
				nvidia,pins = "dap3_fs_pp0";
				nvidia,function = "i2s2";
				nvidia,pull = <TEGRA_PIN_PULL_NONE>;
				nvidia,tristate = <TEGRA_PIN_DISABLE>;
				nvidia,enable-input = <TEGRA_PIN_DISABLE>;
			};
			dap3_din_pp1 {
				nvidia,pins = "dap3_din_pp1";
				nvidia,function = "i2s2";
				nvidia,pull = <TEGRA_PIN_PULL_DOWN>;
				nvidia,tristate = <TEGRA_PIN_DISABLE>;
				nvidia,enable-input = <TEGRA_PIN_DISABLE>;
			};
			dap3_dout_pp2 {
				nvidia,pins = "dap3_dout_pp2";
				nvidia,function = "i2s2";
				nvidia,pull = <TEGRA_PIN_PULL_DOWN>;
				nvidia,tristate = <TEGRA_PIN_DISABLE>;
				nvidia,enable-input = <TEGRA_PIN_ENABLE>;
			};
			dap3_sclk_pp3 {
				nvidia,pins = "dap3_sclk_pp3";
				nvidia,function = "i2s2";
				nvidia,pull = <TEGRA_PIN_PULL_NONE>;
				nvidia,tristate = <TEGRA_PIN_DISABLE>;
				nvidia,enable-input = <TEGRA_PIN_DISABLE>;
			};
			dap4_fs_pp4 {
				nvidia,pins = "dap4_fs_pp4";
				nvidia,function = "i2s3";
				nvidia,pull = <TEGRA_PIN_PULL_NONE>;
				nvidia,tristate = <TEGRA_PIN_DISABLE>;
				nvidia,enable-input = <TEGRA_PIN_ENABLE>;
			};
			dap4_din_pp5 {
				nvidia,pins = "dap4_din_pp5";
				nvidia,function = "i2s3";
				nvidia,pull = <TEGRA_PIN_PULL_NONE>;
				nvidia,tristate = <TEGRA_PIN_DISABLE>;
				nvidia,enable-input = <TEGRA_PIN_ENABLE>;
			};
			dap4_dout_pp6 {
				nvidia,pins = "dap4_dout_pp6";
				nvidia,function = "i2s3";
				nvidia,pull = <TEGRA_PIN_PULL_NONE>;
				nvidia,tristate = <TEGRA_PIN_DISABLE>;
				nvidia,enable-input = <TEGRA_PIN_ENABLE>;
			};
			dap4_sclk_pp7 {
				nvidia,pins = "dap4_sclk_pp7";
				nvidia,function = "i2s3";
				nvidia,pull = <TEGRA_PIN_PULL_NONE>;
				nvidia,tristate = <TEGRA_PIN_DISABLE>;
				nvidia,enable-input = <TEGRA_PIN_ENABLE>;
			};
			kb_col0_pq0 {
				nvidia,pins = "kb_col0_pq0";
				nvidia,function = "kbc";
				nvidia,pull = <TEGRA_PIN_PULL_NONE>;
				nvidia,tristate = <TEGRA_PIN_ENABLE>;
				nvidia,enable-input = <TEGRA_PIN_DISABLE>;
			};
			kb_col1_pq1 {
				nvidia,pins = "kb_col1_pq1";
				nvidia,function = "kbc";
				nvidia,pull = <TEGRA_PIN_PULL_NONE>;
				nvidia,tristate = <TEGRA_PIN_ENABLE>;
				nvidia,enable-input = <TEGRA_PIN_DISABLE>;
			};
			kb_col2_pq2 {
				nvidia,pins = "kb_col2_pq2";
				nvidia,function = "rsvd4";
				nvidia,pull = <TEGRA_PIN_PULL_UP>;
				nvidia,tristate = <TEGRA_PIN_ENABLE>;
				nvidia,enable-input = <TEGRA_PIN_ENABLE>;
			};
			kb_col3_pq3 {
				nvidia,pins = "kb_col3_pq3";
				nvidia,function = "rsvd4";
				nvidia,pull = <TEGRA_PIN_PULL_UP>;
				nvidia,tristate = <TEGRA_PIN_ENABLE>;
				nvidia,enable-input = <TEGRA_PIN_ENABLE>;
			};
			kb_col4_pq4 {
				nvidia,pins = "kb_col4_pq4";
				nvidia,function = "kbc";
				nvidia,pull = <TEGRA_PIN_PULL_NONE>;
				nvidia,tristate = <TEGRA_PIN_ENABLE>;
				nvidia,enable-input = <TEGRA_PIN_ENABLE>;
			};
			kb_col5_pq5 {
				nvidia,pins = "kb_col5_pq5";
				nvidia,function = "kbc";
				nvidia,pull = <TEGRA_PIN_PULL_NONE>;
				nvidia,tristate = <TEGRA_PIN_ENABLE>;
				nvidia,enable-input = <TEGRA_PIN_ENABLE>;
			};
			kb_col6_pq6 {
				nvidia,pins = "kb_col6_pq6";
				nvidia,function = "kbc";
				nvidia,pull = <TEGRA_PIN_PULL_UP>;
				nvidia,tristate = <TEGRA_PIN_DISABLE>;
				nvidia,enable-input = <TEGRA_PIN_ENABLE>;
			};
			kb_col7_pq7 {
				nvidia,pins = "kb_col7_pq7";
				nvidia,function = "kbc";
				nvidia,pull = <TEGRA_PIN_PULL_NONE>;
				nvidia,tristate = <TEGRA_PIN_ENABLE>;
				nvidia,enable-input = <TEGRA_PIN_ENABLE>;
			};
			kb_row0_pr0 {
				nvidia,pins = "kb_row0_pr0";
				nvidia,function = "rsvd4";
				nvidia,pull = <TEGRA_PIN_PULL_UP>;
				nvidia,tristate = <TEGRA_PIN_DISABLE>;
				nvidia,enable-input = <TEGRA_PIN_DISABLE>;
			};
			kb_row1_pr1 {
				nvidia,pins = "kb_row1_pr1";
				nvidia,function = "kbc";
				nvidia,pull = <TEGRA_PIN_PULL_NONE>;
				nvidia,tristate = <TEGRA_PIN_ENABLE>;
				nvidia,enable-input = <TEGRA_PIN_DISABLE>;
			};
			kb_row2_pr2 {
				nvidia,pins = "kb_row2_pr2";
				nvidia,function = "kbc";
				nvidia,pull = <TEGRA_PIN_PULL_NONE>;
				nvidia,tristate = <TEGRA_PIN_ENABLE>;
				nvidia,enable-input = <TEGRA_PIN_ENABLE>;
			};
			kb_row3_pr3 {
				nvidia,pins = "kb_row3_pr3";
				nvidia,function = "kbc";
				nvidia,pull = <TEGRA_PIN_PULL_UP>;
				nvidia,tristate = <TEGRA_PIN_DISABLE>;
				nvidia,enable-input = <TEGRA_PIN_ENABLE>;
			};
			kb_row4_pr4 {
				nvidia,pins = "kb_row4_pr4";
				nvidia,function = "kbc";
				nvidia,pull = <TEGRA_PIN_PULL_NONE>;
				nvidia,tristate = <TEGRA_PIN_ENABLE>;
				nvidia,enable-input = <TEGRA_PIN_ENABLE>;
			};
			kb_row5_pr5 {
				nvidia,pins = "kb_row5_pr5";
				nvidia,function = "kbc";
				nvidia,pull = <TEGRA_PIN_PULL_NONE>;
				nvidia,tristate = <TEGRA_PIN_ENABLE>;
				nvidia,enable-input = <TEGRA_PIN_ENABLE>;
			};
			kb_row6_pr6 {
				nvidia,pins = "kb_row6_pr6";
				nvidia,function = "kbc";
				nvidia,pull = <TEGRA_PIN_PULL_NONE>;
				nvidia,tristate = <TEGRA_PIN_DISABLE>;
				nvidia,enable-input = <TEGRA_PIN_DISABLE>;
			};
			kb_row7_pr7 {
				nvidia,pins = "kb_row7_pr7";
				nvidia,function = "kbc";
				nvidia,pull = <TEGRA_PIN_PULL_DOWN>;
				nvidia,tristate = <TEGRA_PIN_DISABLE>;
				nvidia,enable-input = <TEGRA_PIN_DISABLE>;
			};
			kb_row8_ps0 {
				nvidia,pins = "kb_row8_ps0";
				nvidia,function = "kbc";
				nvidia,pull = <TEGRA_PIN_PULL_NONE>;
				nvidia,tristate = <TEGRA_PIN_DISABLE>;
				nvidia,enable-input = <TEGRA_PIN_DISABLE>;
			};
			kb_row9_ps1 {
				nvidia,pins = "kb_row9_ps1";
				nvidia,function = "kbc";
				nvidia,pull = <TEGRA_PIN_PULL_NONE>;
				nvidia,tristate = <TEGRA_PIN_DISABLE>;
				nvidia,enable-input = <TEGRA_PIN_DISABLE>;
			};
			kb_row10_ps2 {
				nvidia,pins = "kb_row10_ps2";
				nvidia,function = "kbc";
				nvidia,pull = <TEGRA_PIN_PULL_NONE>;
				nvidia,tristate = <TEGRA_PIN_DISABLE>;
				nvidia,enable-input = <TEGRA_PIN_DISABLE>;
			};
			kb_row11_ps3 {
				nvidia,pins = "kb_row11_ps3";
				nvidia,function = "kbc";
				nvidia,pull = <TEGRA_PIN_PULL_NONE>;
				nvidia,tristate = <TEGRA_PIN_DISABLE>;
				nvidia,enable-input = <TEGRA_PIN_ENABLE>;
			};
			kb_row12_ps4 {
				nvidia,pins = "kb_row12_ps4";
				nvidia,function = "kbc";
				nvidia,pull = <TEGRA_PIN_PULL_NONE>;
				nvidia,tristate = <TEGRA_PIN_DISABLE>;
				nvidia,enable-input = <TEGRA_PIN_ENABLE>;
			};
			kb_row13_ps5 {
				nvidia,pins = "kb_row13_ps5";
				nvidia,function = "kbc";
				nvidia,pull = <TEGRA_PIN_PULL_UP>;
				nvidia,tristate = <TEGRA_PIN_DISABLE>;
				nvidia,enable-input = <TEGRA_PIN_ENABLE>;
			};
			kb_row14_ps6 {
				nvidia,pins = "kb_row14_ps6";
				nvidia,function = "kbc";
				nvidia,pull = <TEGRA_PIN_PULL_NONE>;
				nvidia,tristate = <TEGRA_PIN_ENABLE>;
				nvidia,enable-input = <TEGRA_PIN_ENABLE>;
			};
			kb_row15_ps7 {
				nvidia,pins = "kb_row15_ps7";
				nvidia,function = "kbc";
				nvidia,pull = <TEGRA_PIN_PULL_NONE>;
				nvidia,tristate = <TEGRA_PIN_DISABLE>;
				nvidia,enable-input = <TEGRA_PIN_ENABLE>;
			};
			vi_pclk_pt0 {
				nvidia,pins = "vi_pclk_pt0";
				nvidia,function = "sdmmc2";
				nvidia,pull = <TEGRA_PIN_PULL_UP>;
				nvidia,tristate = <TEGRA_PIN_ENABLE>;
				nvidia,enable-input = <TEGRA_PIN_ENABLE>;
			};
			vi_mclk_pt1 {
				nvidia,pins = "vi_mclk_pt1";
				nvidia,function = "vi";
				nvidia,pull = <TEGRA_PIN_PULL_DOWN>;
				nvidia,tristate = <TEGRA_PIN_ENABLE>;
				nvidia,enable-input = <TEGRA_PIN_ENABLE>;
			};
			vi_d10_pt2 {
				nvidia,pins = "vi_d10_pt2";
				nvidia,function = "ddr";
				nvidia,pull = <TEGRA_PIN_PULL_DOWN>;
				nvidia,tristate = <TEGRA_PIN_ENABLE>;
				nvidia,enable-input = <TEGRA_PIN_ENABLE>;
			};
			vi_d11_pt3 {
				nvidia,pins = "vi_d11_pt3";
				nvidia,function = "ddr";
				nvidia,pull = <TEGRA_PIN_PULL_DOWN>;
				nvidia,tristate = <TEGRA_PIN_ENABLE>;
				nvidia,enable-input = <TEGRA_PIN_ENABLE>;
			};
			vi_d0_pt4 {
				nvidia,pins = "vi_d0_pt4";
				nvidia,function = "ddr";
				nvidia,pull = <TEGRA_PIN_PULL_DOWN>;
				nvidia,tristate = <TEGRA_PIN_ENABLE>;
				nvidia,enable-input = <TEGRA_PIN_ENABLE>;
			};
			gen2_i2c_scl_pt5 {
				nvidia,pins = "gen2_i2c_scl_pt5";
				nvidia,function = "i2c2";
				nvidia,pull = <TEGRA_PIN_PULL_NONE>;
				nvidia,tristate = <TEGRA_PIN_DISABLE>;
				nvidia,enable-input = <TEGRA_PIN_ENABLE>;
				nvidia,open-drain = <TEGRA_PIN_DISABLE>;
			};
			gen2_i2c_sda_pt6 {
				nvidia,pins = "gen2_i2c_sda_pt6";
				nvidia,function = "i2c2";
				nvidia,pull = <TEGRA_PIN_PULL_NONE>;
				nvidia,tristate = <TEGRA_PIN_DISABLE>;
				nvidia,enable-input = <TEGRA_PIN_ENABLE>;
				nvidia,open-drain = <TEGRA_PIN_DISABLE>;
			};
			sdmmc4_cmd_pt7 {
				nvidia,pins = "sdmmc4_cmd_pt7";
				nvidia,function = "sdmmc4";
				nvidia,pull = <TEGRA_PIN_PULL_UP>;
				nvidia,tristate = <TEGRA_PIN_DISABLE>;
				nvidia,enable-input = <TEGRA_PIN_ENABLE>;
			};
			pu0 {
				nvidia,pins = "pu0";
				nvidia,function = "rsvd4";
				nvidia,pull = <TEGRA_PIN_PULL_NONE>;
				nvidia,tristate = <TEGRA_PIN_DISABLE>;
				nvidia,enable-input = <TEGRA_PIN_ENABLE>;
			};
			pu1 {
				nvidia,pins = "pu1";
				nvidia,function = "rsvd1";
				nvidia,pull = <TEGRA_PIN_PULL_NONE>;
				nvidia,tristate = <TEGRA_PIN_DISABLE>;
				nvidia,enable-input = <TEGRA_PIN_DISABLE>;
			};
			pu2 {
				nvidia,pins = "pu2";
				nvidia,function = "rsvd1";
				nvidia,pull = <TEGRA_PIN_PULL_NONE>;
				nvidia,tristate = <TEGRA_PIN_DISABLE>;
				nvidia,enable-input = <TEGRA_PIN_ENABLE>;
			};
			pu3 {
				nvidia,pins = "pu3";
				nvidia,function = "rsvd4";
				nvidia,pull = <TEGRA_PIN_PULL_DOWN>;
				nvidia,tristate = <TEGRA_PIN_DISABLE>;
				nvidia,enable-input = <TEGRA_PIN_DISABLE>;
			};
			pu4 {
				nvidia,pins = "pu4";
				nvidia,function = "pwm1";
				nvidia,pull = <TEGRA_PIN_PULL_DOWN>;
				nvidia,tristate = <TEGRA_PIN_DISABLE>;
				nvidia,enable-input = <TEGRA_PIN_DISABLE>;
			};
			pu5 {
				nvidia,pins = "pu5";
				nvidia,function = "pwm2";
				nvidia,pull = <TEGRA_PIN_PULL_DOWN>;
				nvidia,tristate = <TEGRA_PIN_DISABLE>;
				nvidia,enable-input = <TEGRA_PIN_ENABLE>;
			};
			pu6 {
				nvidia,pins = "pu6";
				nvidia,function = "rsvd4";
				nvidia,pull = <TEGRA_PIN_PULL_NONE>;
				nvidia,tristate = <TEGRA_PIN_DISABLE>;
				nvidia,enable-input = <TEGRA_PIN_ENABLE>;
			};
			jtag_rtck_pu7 {
				nvidia,pins = "jtag_rtck_pu7";
				nvidia,function = "rtck";
				nvidia,pull = <TEGRA_PIN_PULL_UP>;
				nvidia,tristate = <TEGRA_PIN_DISABLE>;
				nvidia,enable-input = <TEGRA_PIN_ENABLE>;
			};
			pv0 {
				nvidia,pins = "pv0";
				nvidia,function = "rsvd1";
				nvidia,pull = <TEGRA_PIN_PULL_UP>;
				nvidia,tristate = <TEGRA_PIN_ENABLE>;
				nvidia,enable-input = <TEGRA_PIN_ENABLE>;
			};
			pv1 {
				nvidia,pins = "pv1";
				nvidia,function = "rsvd1";
				nvidia,pull = <TEGRA_PIN_PULL_NONE>;
				nvidia,tristate = <TEGRA_PIN_DISABLE>;
				nvidia,enable-input = <TEGRA_PIN_ENABLE>;
			};
			pv2 {
				nvidia,pins = "pv2";
				nvidia,function = "owr";
				nvidia,pull = <TEGRA_PIN_PULL_NONE>;
				nvidia,tristate = <TEGRA_PIN_ENABLE>;
				nvidia,enable-input = <TEGRA_PIN_DISABLE>;
			};
			pv3 {
				nvidia,pins = "pv3";
				nvidia,function = "clk_12m_out";
				nvidia,pull = <TEGRA_PIN_PULL_NONE>;
				nvidia,tristate = <TEGRA_PIN_ENABLE>;
				nvidia,enable-input = <TEGRA_PIN_ENABLE>;
			};
			ddc_scl_pv4 {
				nvidia,pins = "ddc_scl_pv4";
				nvidia,function = "i2c4";
				nvidia,pull = <TEGRA_PIN_PULL_NONE>;
				nvidia,tristate = <TEGRA_PIN_DISABLE>;
				nvidia,enable-input = <TEGRA_PIN_ENABLE>;
			};
			ddc_sda_pv5 {
				nvidia,pins = "ddc_sda_pv5";
				nvidia,function = "i2c4";
				nvidia,pull = <TEGRA_PIN_PULL_NONE>;
				nvidia,tristate = <TEGRA_PIN_DISABLE>;
				nvidia,enable-input = <TEGRA_PIN_ENABLE>;
			};
			crt_hsync_pv6 {
				nvidia,pins = "crt_hsync_pv6";
				nvidia,function = "crt";
				nvidia,pull = <TEGRA_PIN_PULL_NONE>;
				nvidia,tristate = <TEGRA_PIN_DISABLE>;
				nvidia,enable-input = <TEGRA_PIN_DISABLE>;
			};
			crt_vsync_pv7 {
				nvidia,pins = "crt_vsync_pv7";
				nvidia,function = "crt";
				nvidia,pull = <TEGRA_PIN_PULL_NONE>;
				nvidia,tristate = <TEGRA_PIN_DISABLE>;
				nvidia,enable-input = <TEGRA_PIN_DISABLE>;
			};
			lcd_cs1_n_pw0 {
				nvidia,pins = "lcd_cs1_n_pw0";
				nvidia,function = "displaya";
				nvidia,pull = <TEGRA_PIN_PULL_NONE>;
				nvidia,tristate = <TEGRA_PIN_DISABLE>;
				nvidia,enable-input = <TEGRA_PIN_ENABLE>;
			};
			lcd_m1_pw1 {
				nvidia,pins = "lcd_m1_pw1";
				nvidia,function = "displaya";
				nvidia,pull = <TEGRA_PIN_PULL_NONE>;
				nvidia,tristate = <TEGRA_PIN_DISABLE>;
				nvidia,enable-input = <TEGRA_PIN_DISABLE>;
			};
			spi2_cs1_n_pw2 {
				nvidia,pins = "spi2_cs1_n_pw2";
				nvidia,function = "spi2";
				nvidia,pull = <TEGRA_PIN_PULL_NONE>;
				nvidia,tristate = <TEGRA_PIN_DISABLE>;
				nvidia,enable-input = <TEGRA_PIN_ENABLE>;
			};
			spi2_cs2_n_pw3 {
				nvidia,pins = "spi2_cs2_n_pw3";
				nvidia,function = "spi2";
				nvidia,pull = <TEGRA_PIN_PULL_UP>;
				nvidia,tristate = <TEGRA_PIN_DISABLE>;
				nvidia,enable-input = <TEGRA_PIN_ENABLE>;
			};
			clk1_out_pw4 {
				nvidia,pins = "clk1_out_pw4";
				nvidia,function = "extperiph1";
				nvidia,pull = <TEGRA_PIN_PULL_NONE>;
				nvidia,tristate = <TEGRA_PIN_DISABLE>;
				nvidia,enable-input = <TEGRA_PIN_ENABLE>;
			};
			clk2_out_pw5 {
				nvidia,pins = "clk2_out_pw5";
				nvidia,function = "extperiph2";
				nvidia,pull = <TEGRA_PIN_PULL_NONE>;
				nvidia,tristate = <TEGRA_PIN_DISABLE>;
				nvidia,enable-input = <TEGRA_PIN_ENABLE>;
			};
			uart3_txd_pw6 {
				nvidia,pins = "uart3_txd_pw6";
				nvidia,function = "uartc";
				nvidia,pull = <TEGRA_PIN_PULL_NONE>;
				nvidia,tristate = <TEGRA_PIN_DISABLE>;
				nvidia,enable-input = <TEGRA_PIN_DISABLE>;
			};
			uart3_rxd_pw7 {
				nvidia,pins = "uart3_rxd_pw7";
				nvidia,function = "uartc";
				nvidia,pull = <TEGRA_PIN_PULL_NONE>;
				nvidia,tristate = <TEGRA_PIN_DISABLE>;
				nvidia,enable-input = <TEGRA_PIN_ENABLE>;
			};
			spi2_mosi_px0 {
				nvidia,pins = "spi2_mosi_px0";
				nvidia,function = "spi2";
				nvidia,pull = <TEGRA_PIN_PULL_DOWN>;
				nvidia,tristate = <TEGRA_PIN_DISABLE>;
				nvidia,enable-input = <TEGRA_PIN_DISABLE>;
			};
			spi2_miso_px1 {
				nvidia,pins = "spi2_miso_px1";
				nvidia,function = "spi2";
				nvidia,pull = <TEGRA_PIN_PULL_NONE>;
				nvidia,tristate = <TEGRA_PIN_DISABLE>;
				nvidia,enable-input = <TEGRA_PIN_ENABLE>;
			};
			spi2_sck_px2 {
				nvidia,pins = "spi2_sck_px2";
				nvidia,function = "spi2";
				nvidia,pull = <TEGRA_PIN_PULL_NONE>;
				nvidia,tristate = <TEGRA_PIN_DISABLE>;
				nvidia,enable-input = <TEGRA_PIN_ENABLE>;
			};
			spi2_cs0_n_px3 {
				nvidia,pins = "spi2_cs0_n_px3";
				nvidia,function = "spi6";
				nvidia,pull = <TEGRA_PIN_PULL_UP>;
				nvidia,tristate = <TEGRA_PIN_DISABLE>;
				nvidia,enable-input = <TEGRA_PIN_ENABLE>;
			};
			spi1_mosi_px4 {
				nvidia,pins = "spi1_mosi_px4";
				nvidia,function = "spi1";
				nvidia,pull = <TEGRA_PIN_PULL_NONE>;
				nvidia,tristate = <TEGRA_PIN_DISABLE>;
				nvidia,enable-input = <TEGRA_PIN_ENABLE>;
			};
			spi1_sck_px5 {
				nvidia,pins = "spi1_sck_px5";
				nvidia,function = "spi1";
				nvidia,pull = <TEGRA_PIN_PULL_UP>;
				nvidia,tristate = <TEGRA_PIN_DISABLE>;
				nvidia,enable-input = <TEGRA_PIN_ENABLE>;
			};
			spi1_cs0_n_px6 {
				nvidia,pins = "spi1_cs0_n_px6";
				nvidia,function = "spi1";
				nvidia,pull = <TEGRA_PIN_PULL_NONE>;
				nvidia,tristate = <TEGRA_PIN_DISABLE>;
				nvidia,enable-input = <TEGRA_PIN_ENABLE>;
			};
			spi1_miso_px7 {
				nvidia,pins = "spi1_miso_px7";
				nvidia,function = "spi1";
				nvidia,pull = <TEGRA_PIN_PULL_DOWN>;
				nvidia,tristate = <TEGRA_PIN_DISABLE>;
				nvidia,enable-input = <TEGRA_PIN_DISABLE>;
			};
			ulpi_clk_py0 {
				nvidia,pins = "ulpi_clk_py0";
				nvidia,function = "ulpi";
				nvidia,pull = <TEGRA_PIN_PULL_NONE>;
				nvidia,tristate = <TEGRA_PIN_ENABLE>;
				nvidia,enable-input = <TEGRA_PIN_DISABLE>;
			};
			ulpi_dir_py1 {
				nvidia,pins = "ulpi_dir_py1";
				nvidia,function = "ulpi";
				nvidia,pull = <TEGRA_PIN_PULL_NONE>;
				nvidia,tristate = <TEGRA_PIN_ENABLE>;
				nvidia,enable-input = <TEGRA_PIN_DISABLE>;
			};
			ulpi_nxt_py2 {
				nvidia,pins = "ulpi_nxt_py2";
				nvidia,function = "uartd";
				nvidia,pull = <TEGRA_PIN_PULL_DOWN>;
				nvidia,tristate = <TEGRA_PIN_DISABLE>;
				nvidia,enable-input = <TEGRA_PIN_DISABLE>;
			};
			ulpi_stp_py3 {
				nvidia,pins = "ulpi_stp_py3";
				nvidia,function = "uartd";
				nvidia,pull = <TEGRA_PIN_PULL_DOWN>;
				nvidia,tristate = <TEGRA_PIN_DISABLE>;
				nvidia,enable-input = <TEGRA_PIN_ENABLE>;
			};
			sdmmc1_dat3_py4 {
				nvidia,pins = "sdmmc1_dat3_py4";
				nvidia,function = "sdmmc1";
				nvidia,pull = <TEGRA_PIN_PULL_UP>;
				nvidia,tristate = <TEGRA_PIN_DISABLE>;
				nvidia,enable-input = <TEGRA_PIN_ENABLE>;
			};
			sdmmc1_dat2_py5 {
				nvidia,pins = "sdmmc1_dat2_py5";
				nvidia,function = "sdmmc1";
				nvidia,pull = <TEGRA_PIN_PULL_UP>;
				nvidia,tristate = <TEGRA_PIN_DISABLE>;
				nvidia,enable-input = <TEGRA_PIN_ENABLE>;
			};
			sdmmc1_dat1_py6 {
				nvidia,pins = "sdmmc1_dat1_py6";
				nvidia,function = "sdmmc1";
				nvidia,pull = <TEGRA_PIN_PULL_UP>;
				nvidia,tristate = <TEGRA_PIN_DISABLE>;
				nvidia,enable-input = <TEGRA_PIN_ENABLE>;
			};
			sdmmc1_dat0_py7 {
				nvidia,pins = "sdmmc1_dat0_py7";
				nvidia,function = "sdmmc1";
				nvidia,pull = <TEGRA_PIN_PULL_UP>;
				nvidia,tristate = <TEGRA_PIN_DISABLE>;
				nvidia,enable-input = <TEGRA_PIN_ENABLE>;
			};
			sdmmc1_clk_pz0 {
				nvidia,pins = "sdmmc1_clk_pz0";
				nvidia,function = "sdmmc1";
				nvidia,pull = <TEGRA_PIN_PULL_NONE>;
				nvidia,tristate = <TEGRA_PIN_DISABLE>;
				nvidia,enable-input = <TEGRA_PIN_ENABLE>;
			};
			sdmmc1_cmd_pz1 {
				nvidia,pins = "sdmmc1_cmd_pz1";
				nvidia,function = "sdmmc1";
				nvidia,pull = <TEGRA_PIN_PULL_UP>;
				nvidia,tristate = <TEGRA_PIN_DISABLE>;
				nvidia,enable-input = <TEGRA_PIN_ENABLE>;
			};
			lcd_sdin_pz2 {
				nvidia,pins = "lcd_sdin_pz2";
				nvidia,function = "displaya";
				nvidia,pull = <TEGRA_PIN_PULL_NONE>;
				nvidia,tristate = <TEGRA_PIN_DISABLE>;
				nvidia,enable-input = <TEGRA_PIN_ENABLE>;
			};
			lcd_wr_n_pz3 {
				nvidia,pins = "lcd_wr_n_pz3";
				nvidia,function = "displaya";
				nvidia,pull = <TEGRA_PIN_PULL_UP>;
				nvidia,tristate = <TEGRA_PIN_DISABLE>;
				nvidia,enable-input = <TEGRA_PIN_ENABLE>;
			};
			lcd_sck_pz4 {
				nvidia,pins = "lcd_sck_pz4";
				nvidia,function = "displaya";
				nvidia,pull = <TEGRA_PIN_PULL_NONE>;
				nvidia,tristate = <TEGRA_PIN_DISABLE>;
				nvidia,enable-input = <TEGRA_PIN_ENABLE>;
			};
			sys_clk_req_pz5 {
				nvidia,pins = "sys_clk_req_pz5";
				nvidia,function = "sysclk";
				nvidia,pull = <TEGRA_PIN_PULL_NONE>;
				nvidia,tristate = <TEGRA_PIN_DISABLE>;
				nvidia,enable-input = <TEGRA_PIN_DISABLE>;
			};
			pwr_i2c_scl_pz6 {
				nvidia,pins = "pwr_i2c_scl_pz6";
				nvidia,function = "i2cpwr";
				nvidia,pull = <TEGRA_PIN_PULL_NONE>;
				nvidia,tristate = <TEGRA_PIN_DISABLE>;
				nvidia,enable-input = <TEGRA_PIN_ENABLE>;
				nvidia,open-drain = <TEGRA_PIN_ENABLE>;
			};
			pwr_i2c_sda_pz7 {
				nvidia,pins = "pwr_i2c_sda_pz7";
				nvidia,function = "i2cpwr";
				nvidia,pull = <TEGRA_PIN_PULL_NONE>;
				nvidia,tristate = <TEGRA_PIN_DISABLE>;
				nvidia,enable-input = <TEGRA_PIN_ENABLE>;
				nvidia,open-drain = <TEGRA_PIN_ENABLE>;
			};
			sdmmc4_dat0_paa0 {
				nvidia,pins = "sdmmc4_dat0_paa0";
				nvidia,function = "sdmmc4";
				nvidia,pull = <TEGRA_PIN_PULL_UP>;
				nvidia,tristate = <TEGRA_PIN_DISABLE>;
				nvidia,enable-input = <TEGRA_PIN_ENABLE>;
			};
			sdmmc4_dat1_paa1 {
				nvidia,pins = "sdmmc4_dat1_paa1";
				nvidia,function = "sdmmc4";
				nvidia,pull = <TEGRA_PIN_PULL_UP>;
				nvidia,tristate = <TEGRA_PIN_DISABLE>;
				nvidia,enable-input = <TEGRA_PIN_ENABLE>;
			};
			sdmmc4_dat2_paa2 {
				nvidia,pins = "sdmmc4_dat2_paa2";
				nvidia,function = "sdmmc4";
				nvidia,pull = <TEGRA_PIN_PULL_UP>;
				nvidia,tristate = <TEGRA_PIN_DISABLE>;
				nvidia,enable-input = <TEGRA_PIN_ENABLE>;
			};
			sdmmc4_dat3_paa3 {
				nvidia,pins = "sdmmc4_dat3_paa3";
				nvidia,function = "sdmmc4";
				nvidia,pull = <TEGRA_PIN_PULL_UP>;
				nvidia,tristate = <TEGRA_PIN_DISABLE>;
				nvidia,enable-input = <TEGRA_PIN_ENABLE>;
			};
			sdmmc4_dat4_paa4 {
				nvidia,pins = "sdmmc4_dat4_paa4";
				nvidia,function = "sdmmc4";
				nvidia,pull = <TEGRA_PIN_PULL_UP>;
				nvidia,tristate = <TEGRA_PIN_DISABLE>;
				nvidia,enable-input = <TEGRA_PIN_ENABLE>;
			};
			sdmmc4_dat5_paa5 {
				nvidia,pins = "sdmmc4_dat5_paa5";
				nvidia,function = "sdmmc4";
				nvidia,pull = <TEGRA_PIN_PULL_UP>;
				nvidia,tristate = <TEGRA_PIN_DISABLE>;
				nvidia,enable-input = <TEGRA_PIN_ENABLE>;
			};
			sdmmc4_dat6_paa6 {
				nvidia,pins = "sdmmc4_dat6_paa6";
				nvidia,function = "sdmmc4";
				nvidia,pull = <TEGRA_PIN_PULL_UP>;
				nvidia,tristate = <TEGRA_PIN_DISABLE>;
				nvidia,enable-input = <TEGRA_PIN_ENABLE>;
			};
			sdmmc4_dat7_paa7 {
				nvidia,pins = "sdmmc4_dat7_paa7";
				nvidia,function = "sdmmc4";
				nvidia,pull = <TEGRA_PIN_PULL_UP>;
				nvidia,tristate = <TEGRA_PIN_DISABLE>;
				nvidia,enable-input = <TEGRA_PIN_ENABLE>;
			};
			pbb0 {
				nvidia,pins = "pbb0";
				nvidia,function = "rsvd2";
				nvidia,pull = <TEGRA_PIN_PULL_NONE>;
				nvidia,tristate = <TEGRA_PIN_DISABLE>;
				nvidia,enable-input = <TEGRA_PIN_ENABLE>;
			};
			cam_i2c_scl_pbb1 {
				nvidia,pins = "cam_i2c_scl_pbb1";
				nvidia,function = "i2c3";
				nvidia,pull = <TEGRA_PIN_PULL_NONE>;
				nvidia,tristate = <TEGRA_PIN_DISABLE>;
				nvidia,enable-input = <TEGRA_PIN_ENABLE>;
				nvidia,open-drain = <TEGRA_PIN_DISABLE>;
			};
			cam_i2c_sda_pbb2 {
				nvidia,pins = "cam_i2c_sda_pbb2";
				nvidia,function = "i2c3";
				nvidia,pull = <TEGRA_PIN_PULL_NONE>;
				nvidia,tristate = <TEGRA_PIN_DISABLE>;
				nvidia,enable-input = <TEGRA_PIN_ENABLE>;
				nvidia,open-drain = <TEGRA_PIN_DISABLE>;
			};
			pbb3 {
				nvidia,pins = "pbb3";
				nvidia,function = "vgp3";
				nvidia,pull = <TEGRA_PIN_PULL_NONE>;
				nvidia,tristate = <TEGRA_PIN_DISABLE>;
				nvidia,enable-input = <TEGRA_PIN_ENABLE>;
			};
			pbb4 {
				nvidia,pins = "pbb4";
				nvidia,function = "vgp4";
				nvidia,pull = <TEGRA_PIN_PULL_NONE>;
				nvidia,tristate = <TEGRA_PIN_DISABLE>;
				nvidia,enable-input = <TEGRA_PIN_ENABLE>;
			};
			pbb5 {
				nvidia,pins = "pbb5";
				nvidia,function = "vgp5";
				nvidia,pull = <TEGRA_PIN_PULL_NONE>;
				nvidia,tristate = <TEGRA_PIN_DISABLE>;
				nvidia,enable-input = <TEGRA_PIN_ENABLE>;
			};
			pbb6 {
				nvidia,pins = "pbb6";
				nvidia,function = "vgp6";
				nvidia,pull = <TEGRA_PIN_PULL_NONE>;
				nvidia,tristate = <TEGRA_PIN_DISABLE>;
				nvidia,enable-input = <TEGRA_PIN_ENABLE>;
			};
			pbb7 {
				nvidia,pins = "pbb7";
				nvidia,function = "i2s4";
				nvidia,pull = <TEGRA_PIN_PULL_NONE>;
				nvidia,tristate = <TEGRA_PIN_DISABLE>;
				nvidia,enable-input = <TEGRA_PIN_ENABLE>;
			};
			cam_mclk_pcc0 {
				nvidia,pins = "cam_mclk_pcc0";
				nvidia,function = "vi_alt3";
				nvidia,pull = <TEGRA_PIN_PULL_DOWN>;
				nvidia,tristate = <TEGRA_PIN_DISABLE>;
				nvidia,enable-input = <TEGRA_PIN_ENABLE>;
			};
			pcc1 {
				nvidia,pins = "pcc1";
				nvidia,function = "rsvd2";
				nvidia,pull = <TEGRA_PIN_PULL_NONE>;
				nvidia,tristate = <TEGRA_PIN_DISABLE>;
				nvidia,enable-input = <TEGRA_PIN_ENABLE>;
			};
			pcc2 {
				nvidia,pins = "pcc2";
				nvidia,function = "i2s4";
				nvidia,pull = <TEGRA_PIN_PULL_NONE>;
				nvidia,tristate = <TEGRA_PIN_DISABLE>;
				nvidia,enable-input = <TEGRA_PIN_ENABLE>;
			};
			sdmmc4_rst_n_pcc3 {
				nvidia,pins = "sdmmc4_rst_n_pcc3";
				nvidia,function = "rsvd2";
				nvidia,pull = <TEGRA_PIN_PULL_DOWN>;
				nvidia,tristate = <TEGRA_PIN_DISABLE>;
				nvidia,enable-input = <TEGRA_PIN_ENABLE>;
			};
			sdmmc4_clk_pcc4 {
				nvidia,pins = "sdmmc4_clk_pcc4";
				nvidia,function = "sdmmc4";
				nvidia,pull = <TEGRA_PIN_PULL_NONE>;
				nvidia,tristate = <TEGRA_PIN_DISABLE>;
				nvidia,enable-input = <TEGRA_PIN_ENABLE>;
			};
			clk2_req_pcc5 {
				nvidia,pins = "clk2_req_pcc5";
				nvidia,function = "dap";
				nvidia,pull = <TEGRA_PIN_PULL_NONE>;
				nvidia,tristate = <TEGRA_PIN_DISABLE>;
				nvidia,enable-input = <TEGRA_PIN_ENABLE>;
			};
			pex_l2_rst_n_pcc6 {
				nvidia,pins = "pex_l2_rst_n_pcc6";
				nvidia,function = "pcie";
				nvidia,pull = <TEGRA_PIN_PULL_NONE>;
				nvidia,tristate = <TEGRA_PIN_DISABLE>;
				nvidia,enable-input = <TEGRA_PIN_DISABLE>;
			};
			pex_l2_clkreq_n_pcc7 {
				nvidia,pins = "pex_l2_clkreq_n_pcc7";
				nvidia,function = "pcie";
				nvidia,pull = <TEGRA_PIN_PULL_NONE>;
				nvidia,tristate = <TEGRA_PIN_DISABLE>;
				nvidia,enable-input = <TEGRA_PIN_DISABLE>;
			};
			pex_l0_prsnt_n_pdd0 {
				nvidia,pins = "pex_l0_prsnt_n_pdd0";
				nvidia,function = "pcie";
				nvidia,pull = <TEGRA_PIN_PULL_NONE>;
				nvidia,tristate = <TEGRA_PIN_ENABLE>;
				nvidia,enable-input = <TEGRA_PIN_ENABLE>;
			};
			pex_l0_rst_n_pdd1 {
				nvidia,pins = "pex_l0_rst_n_pdd1";
				nvidia,function = "pcie";
				nvidia,pull = <TEGRA_PIN_PULL_NONE>;
				nvidia,tristate = <TEGRA_PIN_ENABLE>;
				nvidia,enable-input = <TEGRA_PIN_DISABLE>;
			};
			pex_l0_clkreq_n_pdd2 {
				nvidia,pins = "pex_l0_clkreq_n_pdd2";
				nvidia,function = "pcie";
				nvidia,pull = <TEGRA_PIN_PULL_NONE>;
				nvidia,tristate = <TEGRA_PIN_ENABLE>;
				nvidia,enable-input = <TEGRA_PIN_ENABLE>;
			};
			pex_wake_n_pdd3 {
				nvidia,pins = "pex_wake_n_pdd3";
				nvidia,function = "pcie";
				nvidia,pull = <TEGRA_PIN_PULL_NONE>;
				nvidia,tristate = <TEGRA_PIN_DISABLE>;
				nvidia,enable-input = <TEGRA_PIN_ENABLE>;
			};
			pex_l1_prsnt_n_pdd4 {
				nvidia,pins = "pex_l1_prsnt_n_pdd4";
				nvidia,function = "pcie";
				nvidia,pull = <TEGRA_PIN_PULL_NONE>;
				nvidia,tristate = <TEGRA_PIN_ENABLE>;
				nvidia,enable-input = <TEGRA_PIN_ENABLE>;
			};
			pex_l1_rst_n_pdd5 {
				nvidia,pins = "pex_l1_rst_n_pdd5";
				nvidia,function = "pcie";
				nvidia,pull = <TEGRA_PIN_PULL_NONE>;
				nvidia,tristate = <TEGRA_PIN_ENABLE>;
				nvidia,enable-input = <TEGRA_PIN_DISABLE>;
			};
			pex_l1_clkreq_n_pdd6 {
				nvidia,pins = "pex_l1_clkreq_n_pdd6";
				nvidia,function = "pcie";
				nvidia,pull = <TEGRA_PIN_PULL_NONE>;
				nvidia,tristate = <TEGRA_PIN_ENABLE>;
				nvidia,enable-input = <TEGRA_PIN_ENABLE>;
			};
			pex_l2_prsnt_n_pdd7 {
				nvidia,pins = "pex_l2_prsnt_n_pdd7";
				nvidia,function = "pcie";
				nvidia,pull = <TEGRA_PIN_PULL_NONE>;
				nvidia,tristate = <TEGRA_PIN_DISABLE>;
				nvidia,enable-input = <TEGRA_PIN_ENABLE>;
			};
			clk3_out_pee0 {
				nvidia,pins = "clk3_out_pee0";
				nvidia,function = "extperiph3";
				nvidia,pull = <TEGRA_PIN_PULL_NONE>;
				nvidia,tristate = <TEGRA_PIN_DISABLE>;
				nvidia,enable-input = <TEGRA_PIN_DISABLE>;
			};
			clk3_req_pee1 {
				nvidia,pins = "clk3_req_pee1";
				nvidia,function = "dev3";
				nvidia,pull = <TEGRA_PIN_PULL_DOWN>;
				nvidia,tristate = <TEGRA_PIN_DISABLE>;
				nvidia,enable-input = <TEGRA_PIN_ENABLE>;
			};
			clk1_req_pee2 {
				nvidia,pins = "clk1_req_pee2";
				nvidia,function = "dap";
				nvidia,pull = <TEGRA_PIN_PULL_NONE>;
				nvidia,tristate = <TEGRA_PIN_ENABLE>;
				nvidia,enable-input = <TEGRA_PIN_DISABLE>;
			};
			hdmi_cec_pee3 {
				nvidia,pins = "hdmi_cec_pee3";
				nvidia,function = "cec";
				nvidia,pull = <TEGRA_PIN_PULL_NONE>;
				nvidia,tristate = <TEGRA_PIN_DISABLE>;
				nvidia,enable-input = <TEGRA_PIN_ENABLE>;
				nvidia,open-drain = <TEGRA_PIN_DISABLE>;
			};
			owr {
				nvidia,pins = "owr";
				nvidia,function = "owr";
				nvidia,pull = <TEGRA_PIN_PULL_NONE>;
				nvidia,tristate = <TEGRA_PIN_DISABLE>;
				nvidia,enable-input = <TEGRA_PIN_ENABLE>;
			};
			drive_dap1 {
				nvidia,pins = "drive_dap1";
				nvidia,high-speed-mode = <0>;
				nvidia,schmitt = <TEGRA_PIN_ENABLE>;
				nvidia,low-power-mode = <TEGRA_PIN_LP_DRIVE_DIV_1>;
				nvidia,pull-down-strength = <31>;
				nvidia,pull-up-strength = <31>;
				nvidia,slew-rate-rising = <TEGRA_PIN_SLEW_RATE_FASTEST>;
				nvidia,slew-rate-falling = <TEGRA_PIN_SLEW_RATE_FASTEST>;
			};
			drive_dap2 {
				nvidia,pins = "drive_dap2";
				nvidia,high-speed-mode = <0>;
				nvidia,schmitt = <TEGRA_PIN_ENABLE>;
				nvidia,low-power-mode = <TEGRA_PIN_LP_DRIVE_DIV_1>;
				nvidia,pull-down-strength = <31>;
				nvidia,pull-up-strength = <31>;
				nvidia,slew-rate-rising = <TEGRA_PIN_SLEW_RATE_FASTEST>;
				nvidia,slew-rate-falling = <TEGRA_PIN_SLEW_RATE_FASTEST>;
			};
			drive_dbg {
				nvidia,pins = "drive_dbg";
				nvidia,high-speed-mode = <0>;
				nvidia,schmitt = <TEGRA_PIN_ENABLE>;
				nvidia,low-power-mode = <TEGRA_PIN_LP_DRIVE_DIV_1>;
				nvidia,pull-down-strength = <31>;
				nvidia,pull-up-strength = <31>;
				nvidia,slew-rate-rising = <TEGRA_PIN_SLEW_RATE_FASTEST>;
				nvidia,slew-rate-falling = <TEGRA_PIN_SLEW_RATE_FASTEST>;
			};
			drive_at5 {
				nvidia,pins = "drive_at5";
				nvidia,high-speed-mode = <0>;
				nvidia,schmitt = <TEGRA_PIN_ENABLE>;
				nvidia,low-power-mode = <TEGRA_PIN_LP_DRIVE_DIV_1>;
				nvidia,pull-down-strength = <31>;
				nvidia,pull-up-strength = <31>;
				nvidia,slew-rate-rising = <TEGRA_PIN_SLEW_RATE_FASTEST>;
				nvidia,slew-rate-falling = <TEGRA_PIN_SLEW_RATE_FASTEST>;
			};
			drive_gme {
				nvidia,pins = "drive_gme";
				nvidia,high-speed-mode = <0>;
				nvidia,schmitt = <TEGRA_PIN_ENABLE>;
				nvidia,low-power-mode = <TEGRA_PIN_LP_DRIVE_DIV_1>;
				nvidia,pull-down-strength = <31>;
				nvidia,pull-up-strength = <31>;
				nvidia,slew-rate-rising = <TEGRA_PIN_SLEW_RATE_FASTEST>;
				nvidia,slew-rate-falling = <TEGRA_PIN_SLEW_RATE_FASTEST>;
			};
			drive_ddc {
				nvidia,pins = "drive_ddc";
				nvidia,high-speed-mode = <0>;
				nvidia,schmitt = <TEGRA_PIN_ENABLE>;
				nvidia,low-power-mode = <TEGRA_PIN_LP_DRIVE_DIV_1>;
				nvidia,pull-down-strength = <31>;
				nvidia,pull-up-strength = <31>;
				nvidia,slew-rate-rising = <TEGRA_PIN_SLEW_RATE_FASTEST>;
				nvidia,slew-rate-falling = <TEGRA_PIN_SLEW_RATE_FASTEST>;
			};
			drive_ao1 {
				nvidia,pins = "drive_ao1";
				nvidia,high-speed-mode = <0>;
				nvidia,schmitt = <TEGRA_PIN_ENABLE>;
				nvidia,low-power-mode = <TEGRA_PIN_LP_DRIVE_DIV_1>;
				nvidia,pull-down-strength = <31>;
				nvidia,pull-up-strength = <31>;
				nvidia,slew-rate-rising = <TEGRA_PIN_SLEW_RATE_FASTEST>;
				nvidia,slew-rate-falling = <TEGRA_PIN_SLEW_RATE_FASTEST>;
			};
			drive_uart3 {
				nvidia,pins = "drive_uart3";
				nvidia,high-speed-mode = <0>;
				nvidia,schmitt = <TEGRA_PIN_ENABLE>;
				nvidia,low-power-mode = <TEGRA_PIN_LP_DRIVE_DIV_1>;
				nvidia,pull-down-strength = <31>;
				nvidia,pull-up-strength = <31>;
				nvidia,slew-rate-rising = <TEGRA_PIN_SLEW_RATE_FASTEST>;
				nvidia,slew-rate-falling = <TEGRA_PIN_SLEW_RATE_FASTEST>;
			};
			drive_sdio1 {
				nvidia,pins = "drive_sdio1";
				nvidia,high-speed-mode = <0>;
				nvidia,schmitt = <TEGRA_PIN_DISABLE>;
				nvidia,pull-down-strength = <46>;
				nvidia,pull-up-strength = <42>;
				nvidia,slew-rate-rising = <TEGRA_PIN_SLEW_RATE_FAST>;
				nvidia,slew-rate-falling = <TEGRA_PIN_SLEW_RATE_FAST>;
			};
			drive_sdio3 {
				nvidia,pins = "drive_sdio3";
				nvidia,high-speed-mode = <0>;
				nvidia,schmitt = <TEGRA_PIN_DISABLE>;
				nvidia,pull-down-strength = <46>;
				nvidia,pull-up-strength = <42>;
				nvidia,slew-rate-rising = <TEGRA_PIN_SLEW_RATE_FAST>;
				nvidia,slew-rate-falling = <TEGRA_PIN_SLEW_RATE_FAST>;
			};
			drive_gma {
				nvidia,pins = "drive_gma";
				nvidia,pull-down-strength = <9>;
				nvidia,pull-up-strength = <9>;
				nvidia,slew-rate-rising = <TEGRA_PIN_SLEW_RATE_SLOWEST>;
				nvidia,slew-rate-falling = <TEGRA_PIN_SLEW_RATE_SLOWEST>;
			};
			drive_gmb {
				nvidia,pins = "drive_gmb";
				nvidia,pull-down-strength = <9>;
				nvidia,pull-up-strength = <9>;
				nvidia,slew-rate-rising = <TEGRA_PIN_SLEW_RATE_SLOWEST>;
				nvidia,slew-rate-falling = <TEGRA_PIN_SLEW_RATE_SLOWEST>;
			};
			drive_gmc {
				nvidia,pins = "drive_gmc";
				nvidia,pull-down-strength = <9>;
				nvidia,pull-up-strength = <9>;
				nvidia,slew-rate-rising = <TEGRA_PIN_SLEW_RATE_SLOWEST>;
				nvidia,slew-rate-falling = <TEGRA_PIN_SLEW_RATE_SLOWEST>;
			};
			drive_gmd {
				nvidia,pins = "drive_gmd";
				nvidia,pull-down-strength = <9>;
				nvidia,pull-up-strength = <9>;
				nvidia,slew-rate-rising = <TEGRA_PIN_SLEW_RATE_SLOWEST>;
				nvidia,slew-rate-falling = <TEGRA_PIN_SLEW_RATE_SLOWEST>;
			};
		};
	};

	pwm: pwm@7000a000 {
		status = "okay";
	};

	i2c@7000c500 {
		clock-frequency = <100000>;
		status = "okay";

		compass@e {
			compatible = "asahi-kasei,ak8974";
			reg = <0x0e>;
			interrupt-parent = <&gpio>;
			interrupts = <TEGRA_GPIO(W, 0) IRQ_TYPE_EDGE_RISING>;
			mount-matrix =	 "0", "-1",  "0",
					"-1",  "0",  "0",
					 "0",  "0", "-1";
		};

		proximity-sensor@28 {
			compatible = "microchip,cap1106";
			interrupt-parent = <&gpio>;
			interrupts = <TEGRA_GPIO(R, 3) IRQ_TYPE_LEVEL_HIGH>;
			reg = <0x28>;

			microchip,irq-active-high;

			linux,keycodes = <KEY_RESERVED>,
					 <KEY_RESERVED>,
					 <KEY_RESERVED>,
					 <KEY_RESERVED>,
					 <KEY_RESERVED>,
					 <KEY_WAKEUP>;

			#address-cells = <1>;
			#size-cells = <0>;

			proximity@1 {
				label = "cap1106:proximity-sense-cs2";
				reg = <1>;
			};

			proximity@5 {
				label = "cap1106:proximity-sense-cs6";
				reg = <5>;
			};
		};

		accelerometer@68 {
			compatible = "invensense,mpu6050";
			reg = <0x68>;
			interrupt-parent = <&gpio>;
			interrupts = <TEGRA_GPIO(X, 1) IRQ_TYPE_EDGE_RISING>;
			mount-matrix =	 "0", "1",  "0",
					 "1", "0",  "0",
					 "0", "0", "-1";
		};
	};

	i2c@7000d000 {
		clock-frequency = <100000>;
		status = "okay";

		rt5640: rt5640@1c {
			compatible = "realtek,rt5640";
			reg = <0x1c>;
			interrupt-parent = <&gpio>;
			interrupts = <TEGRA_GPIO(W, 3) IRQ_TYPE_EDGE_FALLING>;
			realtek,dmic1-data-pin = <1>;
			realtek,dmic2-data-pin = <0>;
			realtek,in1-differential;
		};

		max77663@3c {
			compatible = "maxim,max77663";
			interrupts = <GIC_SPI 86 IRQ_TYPE_LEVEL_HIGH>;
			reg = <0x3c>;

			system-power-controller;

			fps {
				fps0 {
					maxim,fps-event-source = <MAX77620_FPS_EVENT_SRC_EN0>;
				};

				fps1 {
					maxim,fps-event-source = <MAX77620_FPS_EVENT_SRC_EN1>;
				};

				fps2 {
					maxim,fps-event-source = <MAX77620_FPS_EVENT_SRC_EN0>;
				};
			};

			regulators {
				in-sd0-supply = <&vdd_5v0_sys>;
				in-sd1-supply = <&vdd_5v0_sys>;
				in-sd2-supply = <&vdd_5v0_sys>;
				in-sd3-supply = <&vdd_5v0_sys>;
				in-sd4-supply = <&vdd_5v0_sys>;

				in-ldo0-1-supply = <&vdd_5v0_sys>;
				in-ldo2-supply = <&vdd_5v0_sys>;
				in-ldo3-5-supply = <&vdd_5v0_sys>;
				in-ldo4-6-supply = <&vdd_5v0_sys>;
				in-ldo7-8-supply = <&vdd_1v8>;

				cpu_vdd_reg: sd0 {
					regulator-name = "vdd_cpu";
					regulator-min-microvolt = <800000>;
					regulator-max-microvolt = <1250000>;
					regulator-coupled-with = <&core_vdd_reg>;
					regulator-coupled-max-spread = <300000>;
					regulator-max-step-microvolt = <100000>;
					regulator-always-on;
					regulator-boot-on;

					nvidia,tegra-cpu-regulator;
				};

				core_vdd_reg: sd1 {
					regulator-name = "vdd_core";
					regulator-min-microvolt = <950000>;
					regulator-max-microvolt = <1350000>;
					regulator-coupled-with = <&cpu_vdd_reg>;
					regulator-coupled-max-spread = <300000>;
					regulator-max-step-microvolt = <100000>;
					regulator-always-on;
					regulator-boot-on;

					nvidia,tegra-core-regulator;
				};

				vdd_1v8: sd2 {
					regulator-name = "vdd_gen1v8";
					regulator-min-microvolt = <1800000>;
					regulator-max-microvolt = <1800000>;
					regulator-always-on;
					regulator-boot-on;
				};

				sd3 {
					regulator-name = "vdd_ddr3l_1v35";
					regulator-min-microvolt = <1350000>;
					regulator-max-microvolt = <1350000>;
					regulator-always-on;
					regulator-boot-on;
				};

				ldo0 {
					regulator-name = "vdd_ddr_hs";
					regulator-always-on;
					regulator-boot-on;
				};

				ldo2 {
					regulator-name = "vdd_ddr_rx";
					regulator-always-on;
					regulator-boot-on;
				};

				ldo3 {
					regulator-name = "vmmc";
				};

				ldo4 {
					regulator-name = "vdd_rtc";
					regulator-always-on;
				};

				ldo5 {
					regulator-name = "vdd_camera";
				};

				ldo6 {
					regulator-name = "vddio_sdmmc";
				};

				ldo7 {
					regulator-name = "avdd_dsi_csi";
				};

				ldo8 {
					regulator-name = "avdd_pll";
					regulator-always-on;
					regulator-boot-on;
				};
			};
		};

		nct1008: temperature-sensor@4c {
			compatible = "onnn,nct1008";
			reg = <0x4c>;
			#thermal-sensor-cells = <1>;
		};

		bq27541@55 {
			compatible = "ti,bq27541";
			reg = <0x55>;
		};
	};

	pmc@7000e400 {
		status = "okay";
		nvidia,invert-interrupt;
		nvidia,suspend-mode = <1>;
		nvidia,cpu-pwr-good-time = <2000>;
		nvidia,cpu-pwr-off-time = <200>;
		nvidia,core-pwr-good-time = <3845 3845>;
		nvidia,core-pwr-off-time = <0>;
		nvidia,core-power-req-active-high;
		nvidia,sys-clock-req-active-high;
	};

	ahub@70080000 {
		i2s@70080400 {
			status = "okay";
		};
	};

	brcm_wifi_pwrseq: wifi-pwrseq {
		compatible = "mmc-pwrseq-simple";
		clocks = <&tegra_car TEGRA30_CLK_BLINK>;
		clock-names = "ext_clock";
		reset-gpios = <&gpio TEGRA_GPIO(D, 3) GPIO_ACTIVE_LOW>;
		post-power-on-delay-ms = <300>;
		power-off-delay-us = <300>;
	};

	sdhci@78000400 {
		#address-cells = <1>;
		#size-cells = <0>;

		status = "okay";
		bus-width = <4>;
		enable-sdio-wakeup;

		mmc-pwrseq = <&brcm_wifi_pwrseq>;
		vqmmc-supply = <&brcm_wifi_sdio_reg>;

		brcmf: brcmf@1 {
			reg = <1>;
			compatible = "brcm,bcm4329-fmac";
			interrupt-parent = <&gpio>;
			interrupts = <TEGRA_GPIO(O, 4) IRQ_TYPE_LEVEL_HIGH>;
			interrupt-names = "host-wake";
		};
	};

	sdhci@78000600 {
		status = "okay";
		bus-width = <8>;
		non-removable;
	};

	usb@7d000000 {
		compatible = "nvidia,tegra30-udc";
		status = "okay";
		dr_mode = "peripheral";
	};

	usb-phy@7d000000 {
		status = "okay";
		dr_mode = "peripheral";
	};

	backlight: backlight {
		compatible = "pwm-backlight";
		power-supply = <&vdd_bl_reg>;
		pwms = <&pwm 0x0 500000>;
		brightness-levels = <0 255>;
		num-interpolated-steps = <255>;
		default-brightness-level = <15>;
	};

	clocks {
		compatible = "simple-bus";
		#address-cells = <1>;
		#size-cells = <0>;

		clk32k_in: clock@0 {
			compatible = "fixed-clock";
			reg=<0>;
			#clock-cells = <0>;
			clock-frequency = <32768>;
			clock-output-names = "max77663-gpio4";
		};
	};

	cpus {
		cpu0: cpu@0 {
			cpu-supply = <&cpu_vdd_reg>;
			operating-points-v2 = <&cpu0_opp_table>;
			#cooling-cells = <2>;
		};

		cpu@1 {
			cpu-supply = <&cpu_vdd_reg>;
			operating-points-v2 = <&cpu0_opp_table>;
		};

		cpu@2 {
			cpu-supply = <&cpu_vdd_reg>;
			operating-points-v2 = <&cpu0_opp_table>;
		};

		cpu@3 {
			cpu-supply = <&cpu_vdd_reg>;
			operating-points-v2 = <&cpu0_opp_table>;
		};
	};

	firmware {
		trusted-foundations {
			compatible = "tlm,trusted-foundations";
			tlm,version-major = <0x0>;
			tlm,version-minor = <0x0>;
		};
	};

	gpio-keys {
		compatible = "gpio-keys";

		power {
			label = "Power";
			gpios = <&gpio TEGRA_GPIO(V, 0) GPIO_ACTIVE_LOW>;
			linux,code = <KEY_POWER>;
			debounce-interval = <10>;
			wakeup-event-action = <EV_ACT_ASSERTED>;
			wakeup-source = <1>;
		};

		volume-up {
			label = "Volume-up";
			gpios = <&gpio TEGRA_GPIO(Q, 2) GPIO_ACTIVE_LOW>;
			linux,code = <KEY_VOLUMEUP>;
			debounce-interval = <10>;
		};

		volume-down {
			label = "Volume-up";
			gpios = <&gpio TEGRA_GPIO(Q, 3) GPIO_ACTIVE_LOW>;
			linux,code = <KEY_VOLUMEDOWN>;
			debounce-interval = <10>;
		};
	};

	panel: panel {
		compatible = "chunghwa,claa070wp03xg";
		power-supply = <&vdd_pnl_reg>;
		backlight = <&backlight>;
	};

	regulators {
		compatible = "simple-bus";
		#address-cells = <1>;
		#size-cells = <0>;

		vdd_5v0_sys: regulator@0 {
			compatible = "regulator-fixed";
			reg = <0>;
			regulator-name = "vdd_5v0";
			regulator-min-microvolt = <5000000>;
			regulator-max-microvolt = <5000000>;
			regulator-always-on;
			regulator-boot-on;
		};

		regulator@1 {
			compatible = "regulator-fixed";
			reg = <1>;
			regulator-name = "vdd_3v3";
			regulator-min-microvolt = <3300000>;
			regulator-max-microvolt = <3300000>;
			regulator-always-on;
			regulator-boot-on;
		};

		vdd_pnl_reg: regulator@2 {
			compatible = "regulator-gpio";
			reg = <2>;
			regulator-name = "vdd_pnl";
			regulator-min-microvolt = <2800000>;
			regulator-max-microvolt = <2800000>;

			enable-gpio = <&gpio TEGRA_GPIO(N, 6) GPIO_ACTIVE_HIGH>;
			gpios = <&gpio TEGRA_GPIO(W, 1) GPIO_ACTIVE_HIGH>;
			gpios-states = <1>;
			states = <2800000 1 2800000 0>;

			startup-delay-us = <5000>;
			enable-active-high;
		};

		vdd_bl_reg: regulator@3 {
			compatible = "regulator-fixed";
			reg = <3>;
			regulator-name = "vdd_bl";
			regulator-min-microvolt = <2800000>;
			regulator-max-microvolt = <2800000>;
			regulator-enable-ramp-delay = <300000>;
		};

		brcm_wifi_sdio_reg: regulator@4 {
			compatible = "regulator-fixed";
			reg = <4>;
			regulator-name = "brcm_wifi_pwr";
			regulator-min-microvolt = <1800000>;
			regulator-max-microvolt = <1800000>;
			gpio = <&gpio TEGRA_GPIO(D, 4) GPIO_ACTIVE_HIGH>;
			enable-active-high;
		};
	};

	sound {
		compatible = "nvidia,tegra-audio-rt5640-grouper",
			     "nvidia,tegra-audio-rt5640";
		nvidia,model = "NVIDIA Tegra Grouper";

		nvidia,audio-routing =
			"Headphones", "HPOR",
			"Headphones", "HPOL",
			"Speakers", "SPORP",
			"Speakers", "SPORN",
			"Speakers", "SPOLP",
			"Speakers", "SPOLN",
			"Mic Jack", "MICBIAS1",
			"IN2P", "Mic Jack";

		nvidia,i2s-controller = <&tegra_i2s1>;
		nvidia,audio-codec = <&rt5640>;

		nvidia,hp-det-gpios = <&gpio TEGRA_GPIO(W, 2) GPIO_ACTIVE_LOW>;

		clocks = <&tegra_car TEGRA30_CLK_PLL_A>,
			 <&tegra_car TEGRA30_CLK_PLL_A_OUT0>,
			 <&tegra_car TEGRA30_CLK_EXTERN1>;
		clock-names = "pll_a", "pll_a_out0", "mclk";
	};

	thermal-zones {
		nct1008-local {
			polling-delay-passive = <1000>; /* milliseconds */
			polling-delay = <5000>; /* milliseconds */

			thermal-sensors = <&nct1008 0>;

			trips {
				trip0: cpu-alert0 {
					/* start throttling at 50C */
					temperature = <50000>;
					hysteresis = <3000>;
					type = "passive";
				};

				trip1: cpu-crit {
					/* shut down at 60C */
					temperature = <60000>;
					hysteresis = <2000>;
					type = "critical";
				};
			};

			cooling-maps {
				map0 {
					trip = <&trip0>;
					cooling-device = <&cpu0 THERMAL_NO_LIMIT THERMAL_NO_LIMIT>;
				};
			};
		};

		nct1008-remote {
			polling-delay-passive = <1000>; /* milliseconds */
			polling-delay = <0>; /* milliseconds */

			thermal-sensors = <&nct1008 1>;
		};
	};

	memory-controller@7000f000 {
		emc-timings-1 {
			nvidia,ram-code = <1>;

			timing-25500000 {
				clock-frequency = <25500000>;

				nvidia,emem-configuration = <
					0x00020001 /* MC_EMEM_ARB_CFG */
					0xc0000020 /* MC_EMEM_ARB_OUTSTANDING_REQ */
					0x00000001 /* MC_EMEM_ARB_TIMING_RCD */
					0x00000001 /* MC_EMEM_ARB_TIMING_RP */
					0x00000002 /* MC_EMEM_ARB_TIMING_RC */
					0x00000000 /* MC_EMEM_ARB_TIMING_RAS */
					0x00000001 /* MC_EMEM_ARB_TIMING_FAW */
					0x00000001 /* MC_EMEM_ARB_TIMING_RRD */
					0x00000003 /* MC_EMEM_ARB_TIMING_RAP2PRE */
					0x00000008 /* MC_EMEM_ARB_TIMING_WAP2PRE */
					0x00000002 /* MC_EMEM_ARB_TIMING_R2R */
					0x00000001 /* MC_EMEM_ARB_TIMING_W2W */
					0x00000002 /* MC_EMEM_ARB_TIMING_R2W */
					0x00000006 /* MC_EMEM_ARB_TIMING_W2R */
					0x06020102 /* MC_EMEM_ARB_DA_TURNS */
					0x000a0502 /* MC_EMEM_ARB_DA_COVERS */
					0x74830303 /* MC_EMEM_ARB_MISC0 */
					0x001f0000 /* MC_EMEM_ARB_RING1_THROTTLE */
				>;
			};

			timing-51000000 {
				clock-frequency = <51000000>;

				nvidia,emem-configuration = <
					0x00010001 /* MC_EMEM_ARB_CFG */
					0xc0000020 /* MC_EMEM_ARB_OUTSTANDING_REQ */
					0x00000001 /* MC_EMEM_ARB_TIMING_RCD */
					0x00000001 /* MC_EMEM_ARB_TIMING_RP */
					0x00000002 /* MC_EMEM_ARB_TIMING_RC */
					0x00000000 /* MC_EMEM_ARB_TIMING_RAS */
					0x00000001 /* MC_EMEM_ARB_TIMING_FAW */
					0x00000001 /* MC_EMEM_ARB_TIMING_RRD */
					0x00000003 /* MC_EMEM_ARB_TIMING_RAP2PRE */
					0x00000008 /* MC_EMEM_ARB_TIMING_WAP2PRE */
					0x00000002 /* MC_EMEM_ARB_TIMING_R2R */
					0x00000001 /* MC_EMEM_ARB_TIMING_W2W */
					0x00000002 /* MC_EMEM_ARB_TIMING_R2W */
					0x00000006 /* MC_EMEM_ARB_TIMING_W2R */
					0x06020102 /* MC_EMEM_ARB_DA_TURNS */
					0x000a0502 /* MC_EMEM_ARB_DA_COVERS */
					0x73430303 /* MC_EMEM_ARB_MISC0 */
					0x001f0000 /* MC_EMEM_ARB_RING1_THROTTLE */
				>;
			};

			timing-102000000 {
				clock-frequency = <102000000>;

				nvidia,emem-configuration = <
					0x00000001 /* MC_EMEM_ARB_CFG */
					0xc0000030 /* MC_EMEM_ARB_OUTSTANDING_REQ */
					0x00000001 /* MC_EMEM_ARB_TIMING_RCD */
					0x00000001 /* MC_EMEM_ARB_TIMING_RP */
					0x00000003 /* MC_EMEM_ARB_TIMING_RC */
					0x00000000 /* MC_EMEM_ARB_TIMING_RAS */
					0x00000001 /* MC_EMEM_ARB_TIMING_FAW */
					0x00000001 /* MC_EMEM_ARB_TIMING_RRD */
					0x00000003 /* MC_EMEM_ARB_TIMING_RAP2PRE */
					0x00000008 /* MC_EMEM_ARB_TIMING_WAP2PRE */
					0x00000002 /* MC_EMEM_ARB_TIMING_R2R */
					0x00000001 /* MC_EMEM_ARB_TIMING_W2W */
					0x00000002 /* MC_EMEM_ARB_TIMING_R2W */
					0x00000006 /* MC_EMEM_ARB_TIMING_W2R */
					0x06020102 /* MC_EMEM_ARB_DA_TURNS */
					0x000a0503 /* MC_EMEM_ARB_DA_COVERS */
					0x72830504 /* MC_EMEM_ARB_MISC0 */
					0x001f0000 /* MC_EMEM_ARB_RING1_THROTTLE */
				>;
			};

			timing-204000000 {
				clock-frequency = <204000000>;

				nvidia,emem-configuration = <
					0x00000003 /* MC_EMEM_ARB_CFG */
					0xc0000025 /* MC_EMEM_ARB_OUTSTANDING_REQ */
					0x00000001 /* MC_EMEM_ARB_TIMING_RCD */
					0x00000001 /* MC_EMEM_ARB_TIMING_RP */
					0x00000005 /* MC_EMEM_ARB_TIMING_RC */
					0x00000002 /* MC_EMEM_ARB_TIMING_RAS */
					0x00000003 /* MC_EMEM_ARB_TIMING_FAW */
					0x00000001 /* MC_EMEM_ARB_TIMING_RRD */
					0x00000003 /* MC_EMEM_ARB_TIMING_RAP2PRE */
					0x00000008 /* MC_EMEM_ARB_TIMING_WAP2PRE */
					0x00000002 /* MC_EMEM_ARB_TIMING_R2R */
					0x00000001 /* MC_EMEM_ARB_TIMING_W2W */
					0x00000002 /* MC_EMEM_ARB_TIMING_R2W */
					0x00000006 /* MC_EMEM_ARB_TIMING_W2R */
					0x06020102 /* MC_EMEM_ARB_DA_TURNS */
					0x000a0505 /* MC_EMEM_ARB_DA_COVERS */
					0x72440a06 /* MC_EMEM_ARB_MISC0 */
					0x001f0000 /* MC_EMEM_ARB_RING1_THROTTLE */
				>;
			};

			timing-333500000 {
				clock-frequency = <333500000>;

				nvidia,emem-configuration = <
					0x00000005 /* MC_EMEM_ARB_CFG */
					0xc000003d /* MC_EMEM_ARB_OUTSTANDING_REQ */
					0x00000001 /* MC_EMEM_ARB_TIMING_RCD */
					0x00000002 /* MC_EMEM_ARB_TIMING_RP */
					0x00000008 /* MC_EMEM_ARB_TIMING_RC */
					0x00000004 /* MC_EMEM_ARB_TIMING_RAS */
					0x00000004 /* MC_EMEM_ARB_TIMING_FAW */
					0x00000001 /* MC_EMEM_ARB_TIMING_RRD */
					0x00000002 /* MC_EMEM_ARB_TIMING_RAP2PRE */
					0x00000007 /* MC_EMEM_ARB_TIMING_WAP2PRE */
					0x00000002 /* MC_EMEM_ARB_TIMING_R2R */
					0x00000002 /* MC_EMEM_ARB_TIMING_W2W */
					0x00000003 /* MC_EMEM_ARB_TIMING_R2W */
					0x00000006 /* MC_EMEM_ARB_TIMING_W2R */
					0x06030202 /* MC_EMEM_ARB_DA_TURNS */
					0x000b0608 /* MC_EMEM_ARB_DA_COVERS */
					0x70850f09 /* MC_EMEM_ARB_MISC0 */
					0x001f0000 /* MC_EMEM_ARB_RING1_THROTTLE */
				>;
			};

			timing-667000000 {
				clock-frequency = <667000000>;

				nvidia,emem-configuration = <
					0x0000000a /* MC_EMEM_ARB_CFG */
					0xc0000079 /* MC_EMEM_ARB_OUTSTANDING_REQ */
					0x00000003 /* MC_EMEM_ARB_TIMING_RCD */
					0x00000004 /* MC_EMEM_ARB_TIMING_RP */
					0x00000010 /* MC_EMEM_ARB_TIMING_RC */
					0x0000000b /* MC_EMEM_ARB_TIMING_RAS */
					0x0000000a /* MC_EMEM_ARB_TIMING_FAW */
					0x00000001 /* MC_EMEM_ARB_TIMING_RRD */
					0x00000003 /* MC_EMEM_ARB_TIMING_RAP2PRE */
					0x0000000b /* MC_EMEM_ARB_TIMING_WAP2PRE */
					0x00000002 /* MC_EMEM_ARB_TIMING_R2R */
					0x00000002 /* MC_EMEM_ARB_TIMING_W2W */
					0x00000004 /* MC_EMEM_ARB_TIMING_R2W */
					0x00000008 /* MC_EMEM_ARB_TIMING_W2R */
					0x08040202 /* MC_EMEM_ARB_DA_TURNS */
					0x00130b10 /* MC_EMEM_ARB_DA_COVERS */
					0x70ea1f11 /* MC_EMEM_ARB_MISC0 */
					0x001f0000 /* MC_EMEM_ARB_RING1_THROTTLE */
				>;
			};
		};
	};

	memory-controller@7000f400 {
		emc-timings-1 {
			nvidia,ram-code = <1>;

			timing-25500000 {
				clock-frequency = <25500000>;

				nvidia,emc-auto-cal-interval = <0x001fffff>;
				nvidia,emc-mode-1 = <0x80100003>;
				nvidia,emc-mode-2 = <0x80200008>;
				nvidia,emc-mode-reset = <0x80001221>;
				nvidia,emc-zcal-cnt-long = <0x00000040>;
				nvidia,emc-cfg-dyn-self-ref;
				nvidia,emc-cfg-periodic-qrst;

				nvidia,emc-configuration = <
					0x00000001 /* EMC_RC */
					0x00000004 /* EMC_RFC */
					0x00000000 /* EMC_RAS */
					0x00000000 /* EMC_RP */
					0x00000002 /* EMC_R2W */
					0x0000000a /* EMC_W2R */
					0x00000005 /* EMC_R2P */
					0x0000000b /* EMC_W2P */
					0x00000000 /* EMC_RD_RCD */
					0x00000000 /* EMC_WR_RCD */
					0x00000003 /* EMC_RRD */
					0x00000001 /* EMC_REXT */
					0x00000000 /* EMC_WEXT */
					0x00000005 /* EMC_WDV */
					0x00000005 /* EMC_QUSE */
					0x00000004 /* EMC_QRST */
					0x0000000a /* EMC_QSAFE */
					0x0000000b /* EMC_RDV */
					0x000000c0 /* EMC_REFRESH */
					0x00000000 /* EMC_BURST_REFRESH_NUM */
					0x00000030 /* EMC_PRE_REFRESH_REQ_CNT */
					0x00000002 /* EMC_PDEX2WR */
					0x00000002 /* EMC_PDEX2RD */
					0x00000001 /* EMC_PCHG2PDEN */
					0x00000000 /* EMC_ACT2PDEN */
					0x00000007 /* EMC_AR2PDEN */
					0x0000000f /* EMC_RW2PDEN */
					0x00000005 /* EMC_TXSR */
					0x00000005 /* EMC_TXSRDLL */
					0x00000004 /* EMC_TCKE */
					0x00000001 /* EMC_TFAW */
					0x00000000 /* EMC_TRPAB */
					0x00000004 /* EMC_TCLKSTABLE */
					0x00000005 /* EMC_TCLKSTOP */
					0x000000c7 /* EMC_TREFBW */
					0x00000006 /* EMC_QUSE_EXTRA */
					0x00000004 /* EMC_FBIO_CFG6 */
					0x00000000 /* EMC_ODT_WRITE */
					0x00000000 /* EMC_ODT_READ */
					0x00004288 /* EMC_FBIO_CFG5 */
					0x007800a4 /* EMC_CFG_DIG_DLL */
					0x00008000 /* EMC_CFG_DIG_DLL_PERIOD */
					0x000fc000 /* EMC_DLL_XFORM_DQS0 */
					0x000fc000 /* EMC_DLL_XFORM_DQS1 */
					0x000fc000 /* EMC_DLL_XFORM_DQS2 */
					0x000fc000 /* EMC_DLL_XFORM_DQS3 */
					0x000fc000 /* EMC_DLL_XFORM_DQS4 */
					0x000fc000 /* EMC_DLL_XFORM_DQS5 */
					0x000fc000 /* EMC_DLL_XFORM_DQS6 */
					0x000fc000 /* EMC_DLL_XFORM_DQS7 */
					0x00000000 /* EMC_DLL_XFORM_QUSE0 */
					0x00000000 /* EMC_DLL_XFORM_QUSE1 */
					0x00000000 /* EMC_DLL_XFORM_QUSE2 */
					0x00000000 /* EMC_DLL_XFORM_QUSE3 */
					0x00000000 /* EMC_DLL_XFORM_QUSE4 */
					0x00000000 /* EMC_DLL_XFORM_QUSE5 */
					0x00000000 /* EMC_DLL_XFORM_QUSE6 */
					0x00000000 /* EMC_DLL_XFORM_QUSE7 */
					0x00000000 /* EMC_DLI_TRIM_TXDQS0 */
					0x00000000 /* EMC_DLI_TRIM_TXDQS1 */
					0x00000000 /* EMC_DLI_TRIM_TXDQS2 */
					0x00000000 /* EMC_DLI_TRIM_TXDQS3 */
					0x00000000 /* EMC_DLI_TRIM_TXDQS4 */
					0x00000000 /* EMC_DLI_TRIM_TXDQS5 */
					0x00000000 /* EMC_DLI_TRIM_TXDQS6 */
					0x00000000 /* EMC_DLI_TRIM_TXDQS7 */
					0x000fc000 /* EMC_DLL_XFORM_DQ0 */
					0x000fc000 /* EMC_DLL_XFORM_DQ1 */
					0x000fc000 /* EMC_DLL_XFORM_DQ2 */
					0x000fc000 /* EMC_DLL_XFORM_DQ3 */
					0x000002a0 /* EMC_XM2CMDPADCTRL */
					0x0800211c /* EMC_XM2DQSPADCTRL2 */
					0x00000000 /* EMC_XM2DQPADCTRL2 */
					0x77fff884 /* EMC_XM2CLKPADCTRL */
					0x01f1f108 /* EMC_XM2COMPPADCTRL */
					0x05057404 /* EMC_XM2VTTGENPADCTRL */
					0x54000007 /* EMC_XM2VTTGENPADCTRL2 */
					0x08000168 /* EMC_XM2QUSEPADCTRL */
					0x08000000 /* EMC_XM2DQSPADCTRL3 */
					0x00000802 /* EMC_CTT_TERM_CTRL */
					0x00000000 /* EMC_ZCAL_INTERVAL */
					0x00000040 /* EMC_ZCAL_WAIT_CNT */
					0x000c000c /* EMC_MRS_WAIT_CNT */
					0xa0f10000 /* EMC_AUTO_CAL_CONFIG */
					0x00000000 /* EMC_CTT */
					0x00000000 /* EMC_CTT_DURATION */
					0x80000287 /* EMC_DYN_SELF_REF_CONTROL */
					0xe8000000 /* EMC_FBIO_SPARE */
					0xff00ff00 /* EMC_CFG_RSV */
				>;
			};

			timing-51000000 {
				clock-frequency = <51000000>;

				nvidia,emc-auto-cal-interval = <0x001fffff>;
				nvidia,emc-mode-1 = <0x80100003>;
				nvidia,emc-mode-2 = <0x80200008>;
				nvidia,emc-mode-reset = <0x80001221>;
				nvidia,emc-zcal-cnt-long = <0x00000040>;
				nvidia,emc-cfg-dyn-self-ref;
				nvidia,emc-cfg-periodic-qrst;

				nvidia,emc-configuration = <
					0x00000002 /* EMC_RC */
					0x00000008 /* EMC_RFC */
					0x00000001 /* EMC_RAS */
					0x00000000 /* EMC_RP */
					0x00000002 /* EMC_R2W */
					0x0000000a /* EMC_W2R */
					0x00000005 /* EMC_R2P */
					0x0000000b /* EMC_W2P */
					0x00000000 /* EMC_RD_RCD */
					0x00000000 /* EMC_WR_RCD */
					0x00000003 /* EMC_RRD */
					0x00000001 /* EMC_REXT */
					0x00000000 /* EMC_WEXT */
					0x00000005 /* EMC_WDV */
					0x00000005 /* EMC_QUSE */
					0x00000004 /* EMC_QRST */
					0x0000000a /* EMC_QSAFE */
					0x0000000b /* EMC_RDV */
					0x00000181 /* EMC_REFRESH */
					0x00000000 /* EMC_BURST_REFRESH_NUM */
					0x00000060 /* EMC_PRE_REFRESH_REQ_CNT */
					0x00000002 /* EMC_PDEX2WR */
					0x00000002 /* EMC_PDEX2RD */
					0x00000001 /* EMC_PCHG2PDEN */
					0x00000000 /* EMC_ACT2PDEN */
					0x00000007 /* EMC_AR2PDEN */
					0x0000000f /* EMC_RW2PDEN */
					0x00000009 /* EMC_TXSR */
					0x00000009 /* EMC_TXSRDLL */
					0x00000004 /* EMC_TCKE */
					0x00000002 /* EMC_TFAW */
					0x00000000 /* EMC_TRPAB */
					0x00000004 /* EMC_TCLKSTABLE */
					0x00000005 /* EMC_TCLKSTOP */
					0x0000018e /* EMC_TREFBW */
					0x00000006 /* EMC_QUSE_EXTRA */
					0x00000004 /* EMC_FBIO_CFG6 */
					0x00000000 /* EMC_ODT_WRITE */
					0x00000000 /* EMC_ODT_READ */
					0x00004288 /* EMC_FBIO_CFG5 */
					0x007800a4 /* EMC_CFG_DIG_DLL */
					0x00008000 /* EMC_CFG_DIG_DLL_PERIOD */
					0x000fc000 /* EMC_DLL_XFORM_DQS0 */
					0x000fc000 /* EMC_DLL_XFORM_DQS1 */
					0x000fc000 /* EMC_DLL_XFORM_DQS2 */
					0x000fc000 /* EMC_DLL_XFORM_DQS3 */
					0x000fc000 /* EMC_DLL_XFORM_DQS4 */
					0x000fc000 /* EMC_DLL_XFORM_DQS5 */
					0x000fc000 /* EMC_DLL_XFORM_DQS6 */
					0x000fc000 /* EMC_DLL_XFORM_DQS7 */
					0x00000000 /* EMC_DLL_XFORM_QUSE0 */
					0x00000000 /* EMC_DLL_XFORM_QUSE1 */
					0x00000000 /* EMC_DLL_XFORM_QUSE2 */
					0x00000000 /* EMC_DLL_XFORM_QUSE3 */
					0x00000000 /* EMC_DLL_XFORM_QUSE4 */
					0x00000000 /* EMC_DLL_XFORM_QUSE5 */
					0x00000000 /* EMC_DLL_XFORM_QUSE6 */
					0x00000000 /* EMC_DLL_XFORM_QUSE7 */
					0x00000000 /* EMC_DLI_TRIM_TXDQS0 */
					0x00000000 /* EMC_DLI_TRIM_TXDQS1 */
					0x00000000 /* EMC_DLI_TRIM_TXDQS2 */
					0x00000000 /* EMC_DLI_TRIM_TXDQS3 */
					0x00000000 /* EMC_DLI_TRIM_TXDQS4 */
					0x00000000 /* EMC_DLI_TRIM_TXDQS5 */
					0x00000000 /* EMC_DLI_TRIM_TXDQS6 */
					0x00000000 /* EMC_DLI_TRIM_TXDQS7 */
					0x000fc000 /* EMC_DLL_XFORM_DQ0 */
					0x000fc000 /* EMC_DLL_XFORM_DQ1 */
					0x000fc000 /* EMC_DLL_XFORM_DQ2 */
					0x000fc000 /* EMC_DLL_XFORM_DQ3 */
					0x000002a0 /* EMC_XM2CMDPADCTRL */
					0x0800211c /* EMC_XM2DQSPADCTRL2 */
					0x00000000 /* EMC_XM2DQPADCTRL2 */
					0x77fff884 /* EMC_XM2CLKPADCTRL */
					0x01f1f108 /* EMC_XM2COMPPADCTRL */
					0x05057404 /* EMC_XM2VTTGENPADCTRL */
					0x54000007 /* EMC_XM2VTTGENPADCTRL2 */
					0x08000168 /* EMC_XM2QUSEPADCTRL */
					0x08000000 /* EMC_XM2DQSPADCTRL3 */
					0x00000802 /* EMC_CTT_TERM_CTRL */
					0x00000000 /* EMC_ZCAL_INTERVAL */
					0x00000040 /* EMC_ZCAL_WAIT_CNT */
					0x000c000c /* EMC_MRS_WAIT_CNT */
					0xa0f10000 /* EMC_AUTO_CAL_CONFIG */
					0x00000000 /* EMC_CTT */
					0x00000000 /* EMC_CTT_DURATION */
					0x8000040b /* EMC_DYN_SELF_REF_CONTROL */
					0xe8000000 /* EMC_FBIO_SPARE */
					0xff00ff00 /* EMC_CFG_RSV */
				>;
			};

			timing-102000000 {
				clock-frequency = <102000000>;

				nvidia,emc-auto-cal-interval = <0x001fffff>;
				nvidia,emc-mode-1 = <0x80100003>;
				nvidia,emc-mode-2 = <0x80200008>;
				nvidia,emc-mode-reset = <0x80001221>;
				nvidia,emc-zcal-cnt-long = <0x00000040>;
				nvidia,emc-cfg-dyn-self-ref;
				nvidia,emc-cfg-periodic-qrst;

				nvidia,emc-configuration = <
					0x00000005 /* EMC_RC */
					0x00000010 /* EMC_RFC */
					0x00000003 /* EMC_RAS */
					0x00000001 /* EMC_RP */
					0x00000002 /* EMC_R2W */
					0x0000000a /* EMC_W2R */
					0x00000005 /* EMC_R2P */
					0x0000000b /* EMC_W2P */
					0x00000001 /* EMC_RD_RCD */
					0x00000001 /* EMC_WR_RCD */
					0x00000003 /* EMC_RRD */
					0x00000001 /* EMC_REXT */
					0x00000000 /* EMC_WEXT */
					0x00000005 /* EMC_WDV */
					0x00000005 /* EMC_QUSE */
					0x00000004 /* EMC_QRST */
					0x0000000a /* EMC_QSAFE */
					0x0000000b /* EMC_RDV */
					0x00000303 /* EMC_REFRESH */
					0x00000000 /* EMC_BURST_REFRESH_NUM */
					0x000000c0 /* EMC_PRE_REFRESH_REQ_CNT */
					0x00000002 /* EMC_PDEX2WR */
					0x00000002 /* EMC_PDEX2RD */
					0x00000001 /* EMC_PCHG2PDEN */
					0x00000000 /* EMC_ACT2PDEN */
					0x00000007 /* EMC_AR2PDEN */
					0x0000000f /* EMC_RW2PDEN */
					0x00000012 /* EMC_TXSR */
					0x00000012 /* EMC_TXSRDLL */
					0x00000004 /* EMC_TCKE */
					0x00000004 /* EMC_TFAW */
					0x00000000 /* EMC_TRPAB */
					0x00000004 /* EMC_TCLKSTABLE */
					0x00000005 /* EMC_TCLKSTOP */
					0x0000031c /* EMC_TREFBW */
					0x00000006 /* EMC_QUSE_EXTRA */
					0x00000004 /* EMC_FBIO_CFG6 */
					0x00000000 /* EMC_ODT_WRITE */
					0x00000000 /* EMC_ODT_READ */
					0x00004288 /* EMC_FBIO_CFG5 */
					0x007800a4 /* EMC_CFG_DIG_DLL */
					0x00008000 /* EMC_CFG_DIG_DLL_PERIOD */
					0x000fc000 /* EMC_DLL_XFORM_DQS0 */
					0x000fc000 /* EMC_DLL_XFORM_DQS1 */
					0x000fc000 /* EMC_DLL_XFORM_DQS2 */
					0x000fc000 /* EMC_DLL_XFORM_DQS3 */
					0x000fc000 /* EMC_DLL_XFORM_DQS4 */
					0x000fc000 /* EMC_DLL_XFORM_DQS5 */
					0x000fc000 /* EMC_DLL_XFORM_DQS6 */
					0x000fc000 /* EMC_DLL_XFORM_DQS7 */
					0x00000000 /* EMC_DLL_XFORM_QUSE0 */
					0x00000000 /* EMC_DLL_XFORM_QUSE1 */
					0x00000000 /* EMC_DLL_XFORM_QUSE2 */
					0x00000000 /* EMC_DLL_XFORM_QUSE3 */
					0x00000000 /* EMC_DLL_XFORM_QUSE4 */
					0x00000000 /* EMC_DLL_XFORM_QUSE5 */
					0x00000000 /* EMC_DLL_XFORM_QUSE6 */
					0x00000000 /* EMC_DLL_XFORM_QUSE7 */
					0x00000000 /* EMC_DLI_TRIM_TXDQS0 */
					0x00000000 /* EMC_DLI_TRIM_TXDQS1 */
					0x00000000 /* EMC_DLI_TRIM_TXDQS2 */
					0x00000000 /* EMC_DLI_TRIM_TXDQS3 */
					0x00000000 /* EMC_DLI_TRIM_TXDQS4 */
					0x00000000 /* EMC_DLI_TRIM_TXDQS5 */
					0x00000000 /* EMC_DLI_TRIM_TXDQS6 */
					0x00000000 /* EMC_DLI_TRIM_TXDQS7 */
					0x000fc000 /* EMC_DLL_XFORM_DQ0 */
					0x000fc000 /* EMC_DLL_XFORM_DQ1 */
					0x000fc000 /* EMC_DLL_XFORM_DQ2 */
					0x000fc000 /* EMC_DLL_XFORM_DQ3 */
					0x000002a0 /* EMC_XM2CMDPADCTRL */
					0x0800211c /* EMC_XM2DQSPADCTRL2 */
					0x00000000 /* EMC_XM2DQPADCTRL2 */
					0x77fff884 /* EMC_XM2CLKPADCTRL */
					0x01f1f108 /* EMC_XM2COMPPADCTRL */
					0x05057404 /* EMC_XM2VTTGENPADCTRL */
					0x54000007 /* EMC_XM2VTTGENPADCTRL2 */
					0x08000168 /* EMC_XM2QUSEPADCTRL */
					0x08000000 /* EMC_XM2DQSPADCTRL3 */
					0x00000802 /* EMC_CTT_TERM_CTRL */
					0x00000000 /* EMC_ZCAL_INTERVAL */
					0x00000040 /* EMC_ZCAL_WAIT_CNT */
					0x000c000c /* EMC_MRS_WAIT_CNT */
					0xa0f10000 /* EMC_AUTO_CAL_CONFIG */
					0x00000000 /* EMC_CTT */
					0x00000000 /* EMC_CTT_DURATION */
					0x80000713 /* EMC_DYN_SELF_REF_CONTROL */
					0xe8000000 /* EMC_FBIO_SPARE */
					0xff00ff00 /* EMC_CFG_RSV */
				>;
			};

			timing-204000000 {
				clock-frequency = <204000000>;

				nvidia,emc-auto-cal-interval = <0x001fffff>;
				nvidia,emc-mode-1 = <0x80100003>;
				nvidia,emc-mode-2 = <0x80200008>;
				nvidia,emc-mode-reset = <0x80001221>;
				nvidia,emc-zcal-cnt-long = <0x00000040>;
				nvidia,emc-cfg-dyn-self-ref;
				nvidia,emc-cfg-periodic-qrst;

				nvidia,emc-configuration = <
					0x0000000a /* EMC_RC */
					0x00000020 /* EMC_RFC */
					0x00000007 /* EMC_RAS */
					0x00000002 /* EMC_RP */
					0x00000002 /* EMC_R2W */
					0x0000000a /* EMC_W2R */
					0x00000005 /* EMC_R2P */
					0x0000000b /* EMC_W2P */
					0x00000002 /* EMC_RD_RCD */
					0x00000002 /* EMC_WR_RCD */
					0x00000003 /* EMC_RRD */
					0x00000001 /* EMC_REXT */
					0x00000000 /* EMC_WEXT */
					0x00000005 /* EMC_WDV */
					0x00000005 /* EMC_QUSE */
					0x00000004 /* EMC_QRST */
					0x0000000a /* EMC_QSAFE */
					0x0000000b /* EMC_RDV */
					0x00000607 /* EMC_REFRESH */
					0x00000000 /* EMC_BURST_REFRESH_NUM */
					0x00000181 /* EMC_PRE_REFRESH_REQ_CNT */
					0x00000002 /* EMC_PDEX2WR */
					0x00000002 /* EMC_PDEX2RD */
					0x00000001 /* EMC_PCHG2PDEN */
					0x00000000 /* EMC_ACT2PDEN */
					0x00000007 /* EMC_AR2PDEN */
					0x0000000f /* EMC_RW2PDEN */
					0x00000023 /* EMC_TXSR */
					0x00000023 /* EMC_TXSRDLL */
					0x00000004 /* EMC_TCKE */
					0x00000007 /* EMC_TFAW */
					0x00000000 /* EMC_TRPAB */
					0x00000004 /* EMC_TCLKSTABLE */
					0x00000005 /* EMC_TCLKSTOP */
					0x00000638 /* EMC_TREFBW */
					0x00000006 /* EMC_QUSE_EXTRA */
					0x00000006 /* EMC_FBIO_CFG6 */
					0x00000000 /* EMC_ODT_WRITE */
					0x00000000 /* EMC_ODT_READ */
					0x00004288 /* EMC_FBIO_CFG5 */
					0x004400a4 /* EMC_CFG_DIG_DLL */
					0x00008000 /* EMC_CFG_DIG_DLL_PERIOD */
					0x00080000 /* EMC_DLL_XFORM_DQS0 */
					0x00080000 /* EMC_DLL_XFORM_DQS1 */
					0x00080000 /* EMC_DLL_XFORM_DQS2 */
					0x00080000 /* EMC_DLL_XFORM_DQS3 */
					0x00080000 /* EMC_DLL_XFORM_DQS4 */
					0x00080000 /* EMC_DLL_XFORM_DQS5 */
					0x00080000 /* EMC_DLL_XFORM_DQS6 */
					0x00080000 /* EMC_DLL_XFORM_DQS7 */
					0x00000000 /* EMC_DLL_XFORM_QUSE0 */
					0x00000000 /* EMC_DLL_XFORM_QUSE1 */
					0x00000000 /* EMC_DLL_XFORM_QUSE2 */
					0x00000000 /* EMC_DLL_XFORM_QUSE3 */
					0x00000000 /* EMC_DLL_XFORM_QUSE4 */
					0x00000000 /* EMC_DLL_XFORM_QUSE5 */
					0x00000000 /* EMC_DLL_XFORM_QUSE6 */
					0x00000000 /* EMC_DLL_XFORM_QUSE7 */
					0x00000000 /* EMC_DLI_TRIM_TXDQS0 */
					0x00000000 /* EMC_DLI_TRIM_TXDQS1 */
					0x00000000 /* EMC_DLI_TRIM_TXDQS2 */
					0x00000000 /* EMC_DLI_TRIM_TXDQS3 */
					0x00000000 /* EMC_DLI_TRIM_TXDQS4 */
					0x00000000 /* EMC_DLI_TRIM_TXDQS5 */
					0x00000000 /* EMC_DLI_TRIM_TXDQS6 */
					0x00000000 /* EMC_DLI_TRIM_TXDQS7 */
					0x00080000 /* EMC_DLL_XFORM_DQ0 */
					0x00080000 /* EMC_DLL_XFORM_DQ1 */
					0x00080000 /* EMC_DLL_XFORM_DQ2 */
					0x00080000 /* EMC_DLL_XFORM_DQ3 */
					0x000002a0 /* EMC_XM2CMDPADCTRL */
					0x0800211c /* EMC_XM2DQSPADCTRL2 */
					0x00000000 /* EMC_XM2DQPADCTRL2 */
					0x77fff884 /* EMC_XM2CLKPADCTRL */
					0x01f1f108 /* EMC_XM2COMPPADCTRL */
					0x05057404 /* EMC_XM2VTTGENPADCTRL */
					0x54000007 /* EMC_XM2VTTGENPADCTRL2 */
					0x08000168 /* EMC_XM2QUSEPADCTRL */
					0x08000000 /* EMC_XM2DQSPADCTRL3 */
					0x00000802 /* EMC_CTT_TERM_CTRL */
					0x00020000 /* EMC_ZCAL_INTERVAL */
					0x00000100 /* EMC_ZCAL_WAIT_CNT */
					0x000c000c /* EMC_MRS_WAIT_CNT */
					0xa0f10000 /* EMC_AUTO_CAL_CONFIG */
					0x00000000 /* EMC_CTT */
					0x00000000 /* EMC_CTT_DURATION */
					0x80000d22 /* EMC_DYN_SELF_REF_CONTROL */
					0xe8000000 /* EMC_FBIO_SPARE */
					0xff00ff00 /* EMC_CFG_RSV */
				>;
			};

			timing-333500000 {
				clock-frequency = <333500000>;

				nvidia,emc-auto-cal-interval = <0x001fffff>;
				nvidia,emc-mode-1 = <0x80100002>;
				nvidia,emc-mode-2 = <0x80200000>;
				nvidia,emc-mode-reset = <0x80000321>;
				nvidia,emc-zcal-cnt-long = <0x00000040>;

				nvidia,emc-configuration = <
					0x0000000f /* EMC_RC */
					0x00000034 /* EMC_RFC */
					0x0000000a /* EMC_RAS */
					0x00000003 /* EMC_RP */
					0x00000003 /* EMC_R2W */
					0x00000008 /* EMC_W2R */
					0x00000002 /* EMC_R2P */
					0x00000009 /* EMC_W2P */
					0x00000003 /* EMC_RD_RCD */
					0x00000003 /* EMC_WR_RCD */
					0x00000002 /* EMC_RRD */
					0x00000001 /* EMC_REXT */
					0x00000000 /* EMC_WEXT */
					0x00000004 /* EMC_WDV */
					0x00000006 /* EMC_QUSE */
					0x00000004 /* EMC_QRST */
					0x0000000a /* EMC_QSAFE */
					0x0000000c /* EMC_RDV */
					0x000009e9 /* EMC_REFRESH */
					0x00000000 /* EMC_BURST_REFRESH_NUM */
					0x0000027a /* EMC_PRE_REFRESH_REQ_CNT */
					0x00000001 /* EMC_PDEX2WR */
					0x00000008 /* EMC_PDEX2RD */
					0x00000001 /* EMC_PCHG2PDEN */
					0x00000000 /* EMC_ACT2PDEN */
					0x00000007 /* EMC_AR2PDEN */
					0x0000000e /* EMC_RW2PDEN */
					0x00000039 /* EMC_TXSR */
					0x00000200 /* EMC_TXSRDLL */
					0x00000004 /* EMC_TCKE */
					0x0000000a /* EMC_TFAW */
					0x00000000 /* EMC_TRPAB */
					0x00000004 /* EMC_TCLKSTABLE */
					0x00000005 /* EMC_TCLKSTOP */
					0x00000a2a /* EMC_TREFBW */
					0x00000000 /* EMC_QUSE_EXTRA */
					0x00000004 /* EMC_FBIO_CFG6 */
					0x00000000 /* EMC_ODT_WRITE */
					0x00000000 /* EMC_ODT_READ */
					0x00007088 /* EMC_FBIO_CFG5 */
					0x002600a4 /* EMC_CFG_DIG_DLL */
					0x00008000 /* EMC_CFG_DIG_DLL_PERIOD */
					0x0003c000 /* EMC_DLL_XFORM_DQS0 */
					0x0003c000 /* EMC_DLL_XFORM_DQS1 */
					0x0003c000 /* EMC_DLL_XFORM_DQS2 */
					0x0003c000 /* EMC_DLL_XFORM_DQS3 */
					0x00014000 /* EMC_DLL_XFORM_DQS4 */
					0x00014000 /* EMC_DLL_XFORM_DQS5 */
					0x00014000 /* EMC_DLL_XFORM_DQS6 */
					0x00014000 /* EMC_DLL_XFORM_DQS7 */
					0x00000000 /* EMC_DLL_XFORM_QUSE0 */
					0x00000000 /* EMC_DLL_XFORM_QUSE1 */
					0x00000000 /* EMC_DLL_XFORM_QUSE2 */
					0x00000000 /* EMC_DLL_XFORM_QUSE3 */
					0x00000000 /* EMC_DLL_XFORM_QUSE4 */
					0x00000000 /* EMC_DLL_XFORM_QUSE5 */
					0x00000000 /* EMC_DLL_XFORM_QUSE6 */
					0x00000000 /* EMC_DLL_XFORM_QUSE7 */
					0x00000000 /* EMC_DLI_TRIM_TXDQS0 */
					0x00000000 /* EMC_DLI_TRIM_TXDQS1 */
					0x00000000 /* EMC_DLI_TRIM_TXDQS2 */
					0x00000000 /* EMC_DLI_TRIM_TXDQS3 */
					0x00000000 /* EMC_DLI_TRIM_TXDQS4 */
					0x00000000 /* EMC_DLI_TRIM_TXDQS5 */
					0x00000000 /* EMC_DLI_TRIM_TXDQS6 */
					0x00000000 /* EMC_DLI_TRIM_TXDQS7 */
					0x00048000 /* EMC_DLL_XFORM_DQ0 */
					0x00048000 /* EMC_DLL_XFORM_DQ1 */
					0x00048000 /* EMC_DLL_XFORM_DQ2 */
					0x00048000 /* EMC_DLL_XFORM_DQ3 */
					0x000002a0 /* EMC_XM2CMDPADCTRL */
					0x0800013d /* EMC_XM2DQSPADCTRL2 */
					0x00000000 /* EMC_XM2DQPADCTRL2 */
					0x77fff884 /* EMC_XM2CLKPADCTRL */
					0x01f1f508 /* EMC_XM2COMPPADCTRL */
					0x05057404 /* EMC_XM2VTTGENPADCTRL */
					0x54000007 /* EMC_XM2VTTGENPADCTRL2 */
					0x080001e8 /* EMC_XM2QUSEPADCTRL */
					0x08000021 /* EMC_XM2DQSPADCTRL3 */
					0x00000802 /* EMC_CTT_TERM_CTRL */
					0x00020000 /* EMC_ZCAL_INTERVAL */
					0x00000100 /* EMC_ZCAL_WAIT_CNT */
					0x018b000c /* EMC_MRS_WAIT_CNT */
					0xa0f10000 /* EMC_AUTO_CAL_CONFIG */
					0x00000000 /* EMC_CTT */
					0x00000000 /* EMC_CTT_DURATION */
					0x800014d4 /* EMC_DYN_SELF_REF_CONTROL */
					0xe8000000 /* EMC_FBIO_SPARE */
					0xff00ff89 /* EMC_CFG_RSV */
				>;
			};

			timing-667000000 {
				clock-frequency = <667000000>;

				nvidia,emc-auto-cal-interval = <0x001fffff>;
				nvidia,emc-mode-1 = <0x80100002>;
				nvidia,emc-mode-2 = <0x80200018>;
				nvidia,emc-mode-reset = <0x80000b71>;
				nvidia,emc-zcal-cnt-long = <0x00000040>;
				nvidia,emc-cfg-periodic-qrst;

				nvidia,emc-configuration = <
					0x00000020 /* EMC_RC */
					0x0000006a /* EMC_RFC */
					0x00000017 /* EMC_RAS */
					0x00000007 /* EMC_RP */
					0x00000005 /* EMC_R2W */
					0x0000000c /* EMC_W2R */
					0x00000003 /* EMC_R2P */
					0x00000011 /* EMC_W2P */
					0x00000007 /* EMC_RD_RCD */
					0x00000007 /* EMC_WR_RCD */
					0x00000002 /* EMC_RRD */
					0x00000001 /* EMC_REXT */
					0x00000000 /* EMC_WEXT */
					0x00000007 /* EMC_WDV */
					0x0000000a /* EMC_QUSE */
					0x00000009 /* EMC_QRST */
					0x0000000b /* EMC_QSAFE */
					0x00000011 /* EMC_RDV */
					0x00001412 /* EMC_REFRESH */
					0x00000000 /* EMC_BURST_REFRESH_NUM */
					0x00000504 /* EMC_PRE_REFRESH_REQ_CNT */
					0x00000002 /* EMC_PDEX2WR */
					0x0000000e /* EMC_PDEX2RD */
					0x00000001 /* EMC_PCHG2PDEN */
					0x00000000 /* EMC_ACT2PDEN */
					0x0000000c /* EMC_AR2PDEN */
					0x00000016 /* EMC_RW2PDEN */
					0x00000072 /* EMC_TXSR */
					0x00000200 /* EMC_TXSRDLL */
					0x00000005 /* EMC_TCKE */
					0x00000015 /* EMC_TFAW */
					0x00000000 /* EMC_TRPAB */
					0x00000006 /* EMC_TCLKSTABLE */
					0x00000007 /* EMC_TCLKSTOP */
					0x00001453 /* EMC_TREFBW */
					0x0000000b /* EMC_QUSE_EXTRA */
					0x00000006 /* EMC_FBIO_CFG6 */
					0x00000000 /* EMC_ODT_WRITE */
					0x00000000 /* EMC_ODT_READ */
					0x00005088 /* EMC_FBIO_CFG5 */
					0xf00b0191 /* EMC_CFG_DIG_DLL */
					0x00008000 /* EMC_CFG_DIG_DLL_PERIOD */
					0x00000008 /* EMC_DLL_XFORM_DQS0 */
					0x00000008 /* EMC_DLL_XFORM_DQS1 */
					0x00000008 /* EMC_DLL_XFORM_DQS2 */
					0x00000008 /* EMC_DLL_XFORM_DQS3 */
					0x0000000a /* EMC_DLL_XFORM_DQS4 */
					0x0000000a /* EMC_DLL_XFORM_DQS5 */
					0x0000000a /* EMC_DLL_XFORM_DQS6 */
					0x0000000a /* EMC_DLL_XFORM_DQS7 */
					0x00018000 /* EMC_DLL_XFORM_QUSE0 */
					0x00018000 /* EMC_DLL_XFORM_QUSE1 */
					0x00018000 /* EMC_DLL_XFORM_QUSE2 */
					0x00018000 /* EMC_DLL_XFORM_QUSE3 */
					0x00000000 /* EMC_DLL_XFORM_QUSE4 */
					0x00000000 /* EMC_DLL_XFORM_QUSE5 */
					0x00000000 /* EMC_DLL_XFORM_QUSE6 */
					0x00000000 /* EMC_DLL_XFORM_QUSE7 */
					0x00000000 /* EMC_DLI_TRIM_TXDQS0 */
					0x00000000 /* EMC_DLI_TRIM_TXDQS1 */
					0x00000000 /* EMC_DLI_TRIM_TXDQS2 */
					0x00000000 /* EMC_DLI_TRIM_TXDQS3 */
					0x00000000 /* EMC_DLI_TRIM_TXDQS4 */
					0x00000000 /* EMC_DLI_TRIM_TXDQS5 */
					0x00000000 /* EMC_DLI_TRIM_TXDQS6 */
					0x00000000 /* EMC_DLI_TRIM_TXDQS7 */
					0x0000000a /* EMC_DLL_XFORM_DQ0 */
					0x0000000a /* EMC_DLL_XFORM_DQ1 */
					0x0000000a /* EMC_DLL_XFORM_DQ2 */
					0x0000000a /* EMC_DLL_XFORM_DQ3 */
					0x000002a0 /* EMC_XM2CMDPADCTRL */
					0x0800013d /* EMC_XM2DQSPADCTRL2 */
					0x22220000 /* EMC_XM2DQPADCTRL2 */
					0x77fff884 /* EMC_XM2CLKPADCTRL */
					0x01f1f501 /* EMC_XM2COMPPADCTRL */
					0x07077404 /* EMC_XM2VTTGENPADCTRL */
					0x54000000 /* EMC_XM2VTTGENPADCTRL2 */
					0x080001e8 /* EMC_XM2QUSEPADCTRL */
					0x0c000021 /* EMC_XM2DQSPADCTRL3 */
					0x00000802 /* EMC_CTT_TERM_CTRL */
					0x00020000 /* EMC_ZCAL_INTERVAL */
					0x00000100 /* EMC_ZCAL_WAIT_CNT */
					0x0155000c /* EMC_MRS_WAIT_CNT */
					0xa0f10000 /* EMC_AUTO_CAL_CONFIG */
					0x00000000 /* EMC_CTT */
					0x00000000 /* EMC_CTT_DURATION */
					0x800028a5 /* EMC_DYN_SELF_REF_CONTROL */
					0xe8000000 /* EMC_FBIO_SPARE */
					0xff00ff49 /* EMC_CFG_RSV */
				>;
			};
		};
	};
};
